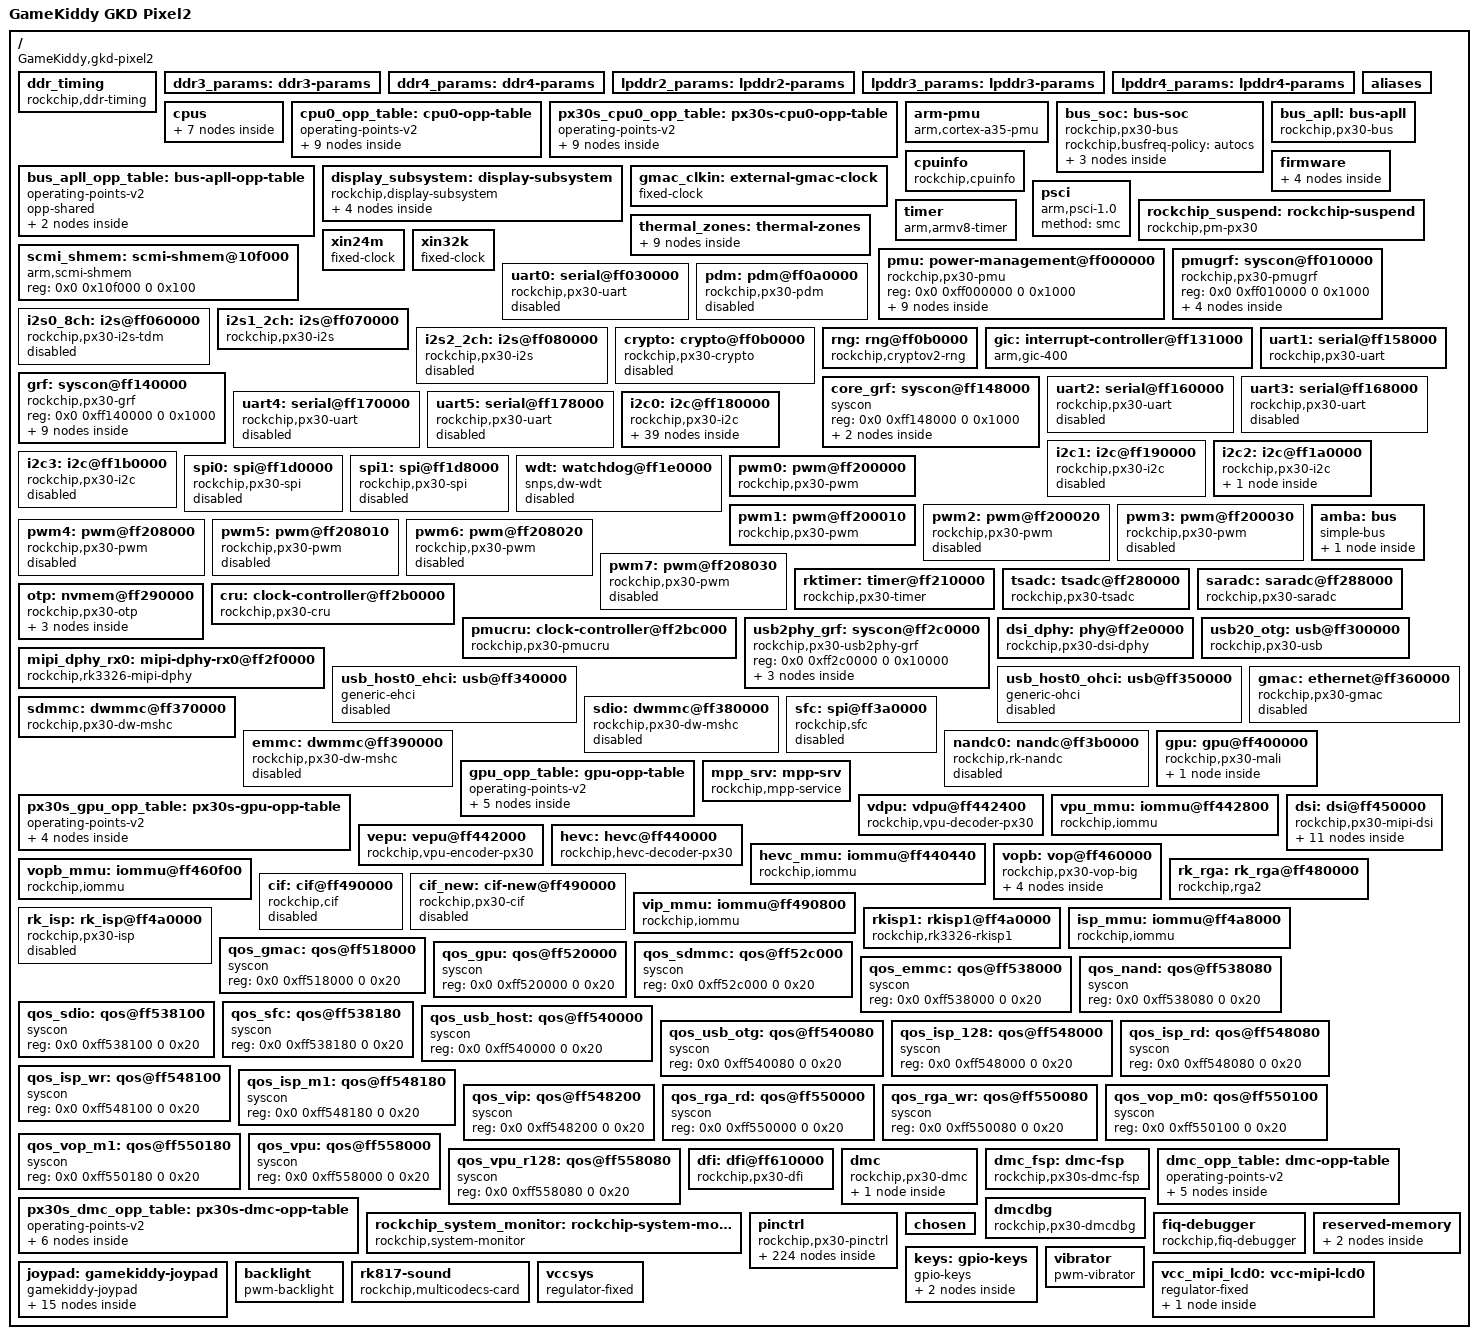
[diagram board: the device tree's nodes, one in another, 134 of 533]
#include <dt-bindings/interrupt-controller/arm-gic.h>
#include <dt-bindings/interrupt-controller/irq.h>
#include <dt-bindings/pinctrl/rockchip.h>
#include <dt-bindings/gpio/gpio.h>

/ {
    compatible = "GameKiddy,gkd-pixel2", "rockchip,rk3326";
    interrupt-parent = <&gic>;
    #address-cells = <2>;
    #size-cells = <2>;
    model = "GameKiddy GKD Pixel2";
    ddr_timing: ddr_timing {
        compatible = "rockchip,ddr-timing";
        ddr2_speed_bin = <0>;
        ddr3_speed_bin = <21>;
        ddr4_speed_bin = <12>;
        pd_idle = <13>;
        sr_idle = <93>;
        sr_mc_gate_idle = <0>;
        srpd_lite_idle = <0>;
        standby_idle = <0>;
        auto_pd_dis_freq = <1066>;
        auto_sr_dis_freq = <800>;
        ddr2_dll_dis_freq = <300>;
        ddr3_dll_dis_freq = <300>;
        ddr4_dll_dis_freq = <625>;
        phy_dll_dis_freq = <400>;
        ddr2_odt_dis_freq = <100>;
        phy_ddr2_odt_dis_freq = <100>;
        ddr2_drv = <1>;
        ddr2_odt = <150>;
        phy_ddr2_ca_drv = <21>;
        phy_ddr2_ck_drv = <18>;
        phy_ddr2_dq_drv = <21>;
        phy_ddr2_odt = <2>;
        ddr3_odt_dis_freq = <400>;
        phy_ddr3_odt_dis_freq = <400>;
        ddr3_drv = <40>;
        ddr3_odt = <120>;
        phy_ddr3_ca_drv = <21>;
        phy_ddr3_ck_drv = <18>;
        phy_ddr3_dq_drv = <21>;
        phy_ddr3_odt = <2>;
        phy_lpddr2_odt_dis_freq = <666>;
        lpddr2_drv = <40>;
        phy_lpddr2_ca_drv = <22>;
        phy_lpddr2_ck_drv = <19>;
        phy_lpddr2_dq_drv = <22>;
        phy_lpddr2_odt = <0>;
        lpddr3_odt_dis_freq = <400>;
        phy_lpddr3_odt_dis_freq = <400>;
        lpddr3_drv = <40>;
        lpddr3_odt = <240>;
        phy_lpddr3_ca_drv = <22>;
        phy_lpddr3_ck_drv = <19>;
        phy_lpddr3_dq_drv = <22>;
        phy_lpddr3_odt = <2>;
        lpddr4_odt_dis_freq = <800>;
        phy_lpddr4_odt_dis_freq = <800>;
        lpddr4_drv = <60>;
        lpddr4_dq_odt = <40>;
        lpddr4_ca_odt = <40>;
        phy_lpddr4_ca_drv = <20>;
        phy_lpddr4_ck_cs_drv = <6>;
        phy_lpddr4_dq_drv = <6>;
        phy_lpddr4_odt = <16>;
        ddr4_odt_dis_freq = <625>;
        phy_ddr4_odt_dis_freq = <625>;
        ddr4_drv = <34>;
        ddr4_odt = <240>;
        phy_ddr4_ca_drv = <22>;
        phy_ddr4_ck_drv = <19>;
        phy_ddr4_dq_drv = <22>;
        phy_ddr4_odt = <2>;
        ddr3a1_ddr4a9_de-skew = <6>;
        ddr3a0_ddr4a10_de-skew = <7>;
        ddr3a3_ddr4a6_de-skew = <7>;
        ddr3a2_ddr4a4_de-skew = <7>;
        ddr3a5_ddr4a8_de-skew = <7>;
        ddr3a4_ddr4a5_de-skew = <7>;
        ddr3a7_ddr4a11_de-skew = <7>;
        ddr3a6_ddr4a7_de-skew = <6>;
        ddr3a9_ddr4a0_de-skew = <7>;
        ddr3a8_ddr4a13_de-skew = <7>;
        ddr3a11_ddr4a3_de-skew = <7>;
        ddr3a10_ddr4cs0_de-skew = <7>;
        ddr3a13_ddr4a2_de-skew = <7>;
        ddr3a12_ddr4ba1_de-skew = <7>;
        ddr3a15_ddr4odt0_de-skew = <7>;
        ddr3a14_ddr4a1_de-skew = <7>;
        ddr3ba1_ddr4a15_de-skew = <7>;
        ddr3ba0_ddr4bg0_de-skew = <7>;
        ddr3ras_ddr4cke_de-skew = <7>;
        ddr3ba2_ddr4ba0_de-skew = <7>;
        ddr3we_ddr4bg1_de-skew = <7>;
        ddr3cas_ddr4a12_de-skew = <7>;
        ddr3ckn_ddr4ckn_de-skew = <7>;
        ddr3ckp_ddr4ckp_de-skew = <7>;
        ddr3cke_ddr4a16_de-skew = <7>;
        ddr3odt0_ddr4a14_de-skew = <7>;
        ddr3cs0_ddr4act_de-skew = <6>;
        ddr3reset_ddr4reset_de-skew = <7>;
        ddr3cs1_ddr4cs1_de-skew = <6>;
        ddr3odt1_ddr4odt1_de-skew = <7>;
        cs0_dm0_rx_de-skew = <7>;
        cs0_dm0_tx_de-skew = <7>;
        cs0_dq0_rx_de-skew = <8>;
        cs0_dq0_tx_de-skew = <8>;
        cs0_dq1_rx_de-skew = <9>;
        cs0_dq1_tx_de-skew = <8>;
        cs0_dq2_rx_de-skew = <8>;
        cs0_dq2_tx_de-skew = <8>;
        cs0_dq3_rx_de-skew = <8>;
        cs0_dq3_tx_de-skew = <8>;
        cs0_dq4_rx_de-skew = <9>;
        cs0_dq4_tx_de-skew = <8>;
        cs0_dq5_rx_de-skew = <9>;
        cs0_dq5_tx_de-skew = <8>;
        cs0_dq6_rx_de-skew = <9>;
        cs0_dq6_tx_de-skew = <8>;
        cs0_dq7_rx_de-skew = <8>;
        cs0_dq7_tx_de-skew = <8>;
        cs0_dqs0_rx_de-skew = <6>;
        cs0_dqs0p_tx_de-skew = <9>;
        cs0_dqs0n_tx_de-skew = <9>;
        cs0_dm1_rx_de-skew = <7>;
        cs0_dm1_tx_de-skew = <6>;
        cs0_dq8_rx_de-skew = <8>;
        cs0_dq8_tx_de-skew = <7>;
        cs0_dq9_rx_de-skew = <9>;
        cs0_dq9_tx_de-skew = <7>;
        cs0_dq10_rx_de-skew = <8>;
        cs0_dq10_tx_de-skew = <8>;
        cs0_dq11_rx_de-skew = <8>;
        cs0_dq11_tx_de-skew = <7>;
        cs0_dq12_rx_de-skew = <8>;
        cs0_dq12_tx_de-skew = <8>;
        cs0_dq13_rx_de-skew = <9>;
        cs0_dq13_tx_de-skew = <7>;
        cs0_dq14_rx_de-skew = <9>;
        cs0_dq14_tx_de-skew = <8>;
        cs0_dq15_rx_de-skew = <9>;
        cs0_dq15_tx_de-skew = <7>;
        cs0_dqs1_rx_de-skew = <7>;
        cs0_dqs1p_tx_de-skew = <9>;
        cs0_dqs1n_tx_de-skew = <9>;
        cs0_dm2_rx_de-skew = <7>;
        cs0_dm2_tx_de-skew = <7>;
        cs0_dq16_rx_de-skew = <9>;
        cs0_dq16_tx_de-skew = <9>;
        cs0_dq17_rx_de-skew = <7>;
        cs0_dq17_tx_de-skew = <9>;
        cs0_dq18_rx_de-skew = <7>;
        cs0_dq18_tx_de-skew = <8>;
        cs0_dq19_rx_de-skew = <7>;
        cs0_dq19_tx_de-skew = <9>;
        cs0_dq20_rx_de-skew = <9>;
        cs0_dq20_tx_de-skew = <9>;
        cs0_dq21_rx_de-skew = <9>;
        cs0_dq21_tx_de-skew = <9>;
        cs0_dq22_rx_de-skew = <8>;
        cs0_dq22_tx_de-skew = <9>;
        cs0_dq23_rx_de-skew = <8>;
        cs0_dq23_tx_de-skew = <9>;
        cs0_dqs2_rx_de-skew = <6>;
        cs0_dqs2p_tx_de-skew = <9>;
        cs0_dqs2n_tx_de-skew = <9>;
        cs0_dm3_rx_de-skew = <7>;
        cs0_dm3_tx_de-skew = <7>;
        cs0_dq24_rx_de-skew = <8>;
        cs0_dq24_tx_de-skew = <8>;
        cs0_dq25_rx_de-skew = <9>;
        cs0_dq25_tx_de-skew = <9>;
        cs0_dq26_rx_de-skew = <9>;
        cs0_dq26_tx_de-skew = <8>;
        cs0_dq27_rx_de-skew = <9>;
        cs0_dq27_tx_de-skew = <8>;
        cs0_dq28_rx_de-skew = <9>;
        cs0_dq28_tx_de-skew = <9>;
        cs0_dq29_rx_de-skew = <9>;
        cs0_dq29_tx_de-skew = <9>;
        cs0_dq30_rx_de-skew = <8>;
        cs0_dq30_tx_de-skew = <8>;
        cs0_dq31_rx_de-skew = <8>;
        cs0_dq31_tx_de-skew = <8>;
        cs0_dqs3_rx_de-skew = <7>;
        cs0_dqs3p_tx_de-skew = <9>;
        cs0_dqs3n_tx_de-skew = <9>;
        cs1_dm0_rx_de-skew = <7>;
        cs1_dm0_tx_de-skew = <7>;
        cs1_dq0_rx_de-skew = <8>;
        cs1_dq0_tx_de-skew = <8>;
        cs1_dq1_rx_de-skew = <9>;
        cs1_dq1_tx_de-skew = <8>;
        cs1_dq2_rx_de-skew = <8>;
        cs1_dq2_tx_de-skew = <8>;
        cs1_dq3_rx_de-skew = <8>;
        cs1_dq3_tx_de-skew = <8>;
        cs1_dq4_rx_de-skew = <8>;
        cs1_dq4_tx_de-skew = <8>;
        cs1_dq5_rx_de-skew = <9>;
        cs1_dq5_tx_de-skew = <8>;
        cs1_dq6_rx_de-skew = <9>;
        cs1_dq6_tx_de-skew = <8>;
        cs1_dq7_rx_de-skew = <8>;
        cs1_dq7_tx_de-skew = <8>;
        cs1_dqs0_rx_de-skew = <6>;
        cs1_dqs0p_tx_de-skew = <9>;
        cs1_dqs0n_tx_de-skew = <9>;
        cs1_dm1_rx_de-skew = <7>;
        cs1_dm1_tx_de-skew = <7>;
        cs1_dq8_rx_de-skew = <8>;
        cs1_dq8_tx_de-skew = <8>;
        cs1_dq9_rx_de-skew = <8>;
        cs1_dq9_tx_de-skew = <7>;
        cs1_dq10_rx_de-skew = <7>;
        cs1_dq10_tx_de-skew = <8>;
        cs1_dq11_rx_de-skew = <8>;
        cs1_dq11_tx_de-skew = <8>;
        cs1_dq12_rx_de-skew = <8>;
        cs1_dq12_tx_de-skew = <7>;
        cs1_dq13_rx_de-skew = <8>;
        cs1_dq13_tx_de-skew = <8>;
        cs1_dq14_rx_de-skew = <8>;
        cs1_dq14_tx_de-skew = <8>;
        cs1_dq15_rx_de-skew = <8>;
        cs1_dq15_tx_de-skew = <7>;
        cs1_dqs1_rx_de-skew = <7>;
        cs1_dqs1p_tx_de-skew = <9>;
        cs1_dqs1n_tx_de-skew = <9>;
        cs1_dm2_rx_de-skew = <7>;
        cs1_dm2_tx_de-skew = <8>;
        cs1_dq16_rx_de-skew = <8>;
        cs1_dq16_tx_de-skew = <9>;
        cs1_dq17_rx_de-skew = <8>;
        cs1_dq17_tx_de-skew = <9>;
        cs1_dq18_rx_de-skew = <7>;
        cs1_dq18_tx_de-skew = <8>;
        cs1_dq19_rx_de-skew = <8>;
        cs1_dq19_tx_de-skew = <9>;
        cs1_dq20_rx_de-skew = <9>;
        cs1_dq20_tx_de-skew = <9>;
        cs1_dq21_rx_de-skew = <9>;
        cs1_dq21_tx_de-skew = <9>;
        cs1_dq22_rx_de-skew = <8>;
        cs1_dq22_tx_de-skew = <9>;
        cs1_dq23_rx_de-skew = <8>;
        cs1_dq23_tx_de-skew = <9>;
        cs1_dqs2_rx_de-skew = <6>;
        cs1_dqs2p_tx_de-skew = <9>;
        cs1_dqs2n_tx_de-skew = <9>;
        cs1_dm3_rx_de-skew = <7>;
        cs1_dm3_tx_de-skew = <7>;
        cs1_dq24_rx_de-skew = <8>;
        cs1_dq24_tx_de-skew = <9>;
        cs1_dq25_rx_de-skew = <9>;
        cs1_dq25_tx_de-skew = <9>;
        cs1_dq26_rx_de-skew = <9>;
        cs1_dq26_tx_de-skew = <8>;
        cs1_dq27_rx_de-skew = <8>;
        cs1_dq27_tx_de-skew = <8>;
        cs1_dq28_rx_de-skew = <9>;
        cs1_dq28_tx_de-skew = <9>;
        cs1_dq29_rx_de-skew = <9>;
        cs1_dq29_tx_de-skew = <9>;
        cs1_dq30_rx_de-skew = <9>;
        cs1_dq30_tx_de-skew = <8>;
        cs1_dq31_rx_de-skew = <8>;
        cs1_dq31_tx_de-skew = <8>;
        cs1_dqs3_rx_de-skew = <7>;
        cs1_dqs3p_tx_de-skew = <9>;
        cs1_dqs3n_tx_de-skew = <9>;
    };
    ddr3_params: ddr3-params {
        version = <257>;
        expanded_version = <0>;
        reserved = <0>;
        freq_0 = <666>;
        freq_1 = <194>;
        freq_2 = <328>;
        freq_3 = <666>;
        freq_4 = <0>;
        freq_5 = <0>;
        pd_idle = <13>;
        sr_idle = <93>;
        sr_mc_gate_idle = <0>;
        srpd_lite_idle = <0>;
        standby_idle = <0>;
        pd_dis_freq = <1066>;
        sr_dis_freq = <800>;
        dram_dll_dis_freq = <300>;
        phy_dll_dis_freq = <0>;
        phy_dq_drv_odten = <33>;
        phy_ca_drv_odten = <33>;
        phy_clk_drv_odten = <33>;
        dram_dq_drv_odten = <34>;
        phy_dq_drv_odtoff = <33>;
        phy_ca_drv_odtoff = <33>;
        phy_clk_drv_odtoff = <33>;
        dram_dq_drv_odtoff = <34>;
        dram_odt = <120>;
        phy_odt = <133>;
        phy_odt_puup_en = <1>;
        phy_odt_pudn_en = <1>;
        dram_dq_odt_en_freq = <333>;
        phy_odt_en_freq = <333>;
        phy_dq_sr_odten = <15>;
        phy_ca_sr_odten = <3>;
        phy_clk_sr_odten = <3>;
        phy_dq_sr_odtoff = <15>;
        phy_ca_sr_odtoff = <3>;
        phy_clk_sr_odtoff = <3>;
        ssmod_downspread = <0>;
        ssmod_div = <0>;
        ssmod_spread = <0>;
        mode_2t = <0>;
        speed_bin = <21>;
        dram_ext_temp = <0>;
        byte_map = <177>;
        dq_map_cs0_dq_l = <0>;
        dq_map_cs0_dq_h = <0>;
        dq_map_cs1_dq_l = <0>;
        dq_map_cs1_dq_h = <0>;
    };
    ddr4_params: ddr4-params {
        version = <257>;
        expanded_version = <0>;
        reserved = <0>;
        freq_0 = <666>;
        freq_1 = <194>;
        freq_2 = <328>;
        freq_3 = <666>;
        freq_4 = <0>;
        freq_5 = <0>;
        pd_idle = <13>;
        sr_idle = <93>;
        sr_mc_gate_idle = <0>;
        srpd_lite_idle = <0>;
        standby_idle = <0>;
        pd_dis_freq = <1066>;
        sr_dis_freq = <800>;
        dram_dll_dis_freq = <500>;
        phy_dll_dis_freq = <0>;
        phy_dq_drv_odten = <33>;
        phy_ca_drv_odten = <33>;
        phy_clk_drv_odten = <33>;
        dram_dq_drv_odten = <34>;
        phy_dq_drv_odtoff = <33>;
        phy_ca_drv_odtoff = <33>;
        phy_clk_drv_odtoff = <33>;
        dram_dq_drv_odtoff = <34>;
        dram_odt = <120>;
        phy_odt = <121>;
        phy_odt_puup_en = <1>;
        phy_odt_pudn_en = <1>;
        dram_dq_odt_en_freq = <500>;
        phy_odt_en_freq = <500>;
        phy_dq_sr_odten = <14>;
        phy_ca_sr_odten = <1>;
        phy_clk_sr_odten = <1>;
        phy_dq_sr_odtoff = <14>;
        phy_ca_sr_odtoff = <1>;
        phy_clk_sr_odtoff = <1>;
        ssmod_downspread = <0>;
        ssmod_div = <0>;
        ssmod_spread = <0>;
        mode_2t = <0>;
        speed_bin = <12>;
        dram_ext_temp = <0>;
        byte_map = <177>;
        dq_map_cs0_dq_l = <328950387>;
        dq_map_cs0_dq_h = <657289026>;
        dq_map_cs1_dq_l = <1187919654>;
        dq_map_cs1_dq_h = <1920481815>;
    };
    lpddr2_params: lpddr2-params {
        version = <257>;
        expanded_version = <0>;
        reserved = <0>;
        freq_0 = <528>;
        freq_1 = <194>;
        freq_2 = <328>;
        freq_3 = <528>;
        freq_4 = <0>;
        freq_5 = <0>;
        pd_idle = <13>;
        sr_idle = <93>;
        sr_mc_gate_idle = <0>;
        srpd_lite_idle = <0>;
        standby_idle = <0>;
        pd_dis_freq = <1066>;
        sr_dis_freq = <800>;
        dram_dll_dis_freq = <0>;
        phy_dll_dis_freq = <0>;
        phy_dq_drv_odten = <33>;
        phy_ca_drv_odten = <33>;
        phy_clk_drv_odten = <33>;
        dram_dq_drv_odten = <34>;
        phy_dq_drv_odtoff = <33>;
        phy_ca_drv_odtoff = <33>;
        phy_clk_drv_odtoff = <33>;
        dram_dq_drv_odtoff = <34>;
        dram_odt = <0>;
        phy_odt = <0>;
        phy_odt_puup_en = <0>;
        phy_odt_pudn_en = <0>;
        dram_dq_odt_en_freq = <625>;
        phy_odt_en_freq = <625>;
        phy_dq_sr_odten = <14>;
        phy_ca_sr_odten = <1>;
        phy_clk_sr_odten = <1>;
        phy_dq_sr_odtoff = <14>;
        phy_ca_sr_odtoff = <1>;
        phy_clk_sr_odtoff = <1>;
        ssmod_downspread = <0>;
        ssmod_div = <0>;
        ssmod_spread = <0>;
        mode_2t = <0>;
        speed_bin = <0>;
        dram_ext_temp = <0>;
        byte_map = <228>;
        dq_map_cs0_dq_l = <0>;
        dq_map_cs0_dq_h = <0>;
        dq_map_cs1_dq_l = <0>;
        dq_map_cs1_dq_h = <0>;
    };
    lpddr3_params: lpddr3-params {
        version = <257>;
        expanded_version = <0>;
        reserved = <0>;
        freq_0 = <666>;
        freq_1 = <194>;
        freq_2 = <328>;
        freq_3 = <666>;
        freq_4 = <0>;
        freq_5 = <0>;
        pd_idle = <13>;
        sr_idle = <93>;
        sr_mc_gate_idle = <0>;
        srpd_lite_idle = <0>;
        standby_idle = <0>;
        pd_dis_freq = <1066>;
        sr_dis_freq = <800>;
        dram_dll_dis_freq = <0>;
        phy_dll_dis_freq = <0>;
        phy_dq_drv_odten = <33>;
        phy_ca_drv_odten = <33>;
        phy_clk_drv_odten = <33>;
        dram_dq_drv_odten = <34>;
        phy_dq_drv_odtoff = <33>;
        phy_ca_drv_odtoff = <33>;
        phy_clk_drv_odtoff = <33>;
        dram_dq_drv_odtoff = <34>;
        dram_odt = <240>;
        phy_odt = <121>;
        phy_odt_puup_en = <1>;
        phy_odt_pudn_en = <1>;
        dram_dq_odt_en_freq = <333>;
        phy_odt_en_freq = <333>;
        phy_dq_sr_odten = <0>;
        phy_ca_sr_odten = <0>;
        phy_clk_sr_odten = <0>;
        phy_dq_sr_odtoff = <0>;
        phy_ca_sr_odtoff = <0>;
        phy_clk_sr_odtoff = <0>;
        ssmod_downspread = <0>;
        ssmod_div = <0>;
        ssmod_spread = <0>;
        mode_2t = <0>;
        speed_bin = <0>;
        dram_ext_temp = <0>;
        byte_map = <228>;
        dq_map_cs0_dq_l = <0>;
        dq_map_cs0_dq_h = <0>;
        dq_map_cs1_dq_l = <0>;
        dq_map_cs1_dq_h = <0>;
    };
    lpddr4_params: lpddr4-params {
        version = <257>;
        expanded_version = <0>;
        reserved = <0>;
        freq_0 = <1056>;
        freq_1 = <194>;
        freq_2 = <328>;
        freq_3 = <1056>;
        freq_4 = <0>;
        freq_5 = <0>;
        pd_idle = <13>;
        sr_idle = <93>;
        sr_mc_gate_idle = <0>;
        srpd_lite_idle = <0>;
        standby_idle = <0>;
        pd_dis_freq = <1066>;
        sr_dis_freq = <800>;
        dram_dll_dis_freq = <0>;
        phy_dll_dis_freq = <0>;
        phy_dq_drv_odten = <44>;
        phy_ca_drv_odten = <38>;
        phy_clk_drv_odten = <47>;
        dram_dq_drv_odten = <40>;
        phy_dq_drv_odtoff = <44>;
        phy_ca_drv_odtoff = <38>;
        phy_clk_drv_odtoff = <47>;
        dram_dq_drv_odtoff = <40>;
        dram_odt = <60>;
        phy_odt = <80>;
        phy_odt_puup_en = <0>;
        phy_odt_pudn_en = <0>;
        dram_dq_odt_en_freq = <800>;
        phy_odt_en_freq = <800>;
        phy_dq_sr_odten = <7>;
        phy_ca_sr_odten = <1>;
        phy_clk_sr_odten = <1>;
        phy_dq_sr_odtoff = <7>;
        phy_ca_sr_odtoff = <1>;
        phy_clk_sr_odtoff = <1>;
        ssmod_downspread = <0>;
        ssmod_div = <0>;
        ssmod_spread = <0>;
        mode_2t = <0>;
        speed_bin = <0>;
        dram_ext_temp = <0>;
        byte_map = <228>;
        dq_map_cs0_dq_l = <0>;
        dq_map_cs0_dq_h = <0>;
        dq_map_cs1_dq_l = <0>;
        dq_map_cs1_dq_h = <0>;
        lp4_ca_odt = <120>;
        lp4_drv_pu_cal_odten = <0>;
        lp4_drv_pu_cal_odtoff = <0>;
        phy_lp4_drv_pulldown_en_odten = <0>;
        phy_lp4_drv_pulldown_en_odtoff = <0>;
        lp4_ca_odt_en_freq = <800>;
        phy_lp4_cs_drv_odten = <0>;
        phy_lp4_cs_drv_odtoff = <0>;
        lp4_odte_ck_en = <1>;
        lp4_odte_cs_en = <1>;
        lp4_odtd_ca_en = <0>;
        phy_lp4_dq_vref_odten = <200>;
        lp4_dq_vref_odten = <276>;
        lp4_ca_vref_odten = <380>;
        phy_lp4_dq_vref_odtoff = <420>;
        lp4_dq_vref_odtoff = <420>;
        lp4_ca_vref_odtoff = <420>;
    };
    aliases {
        ethernet0 = "/ethernet@ff360000";
        gpio0 = "/pinctrl/gpio0@ff040000";
        gpio1 = "/pinctrl/gpio1@ff250000";
        gpio2 = "/pinctrl/gpio2@ff260000";
        gpio3 = "/pinctrl/gpio3@ff270000";
        i2c0 = "/i2c@ff180000";
        i2c1 = "/i2c@ff190000";
        i2c2 = "/i2c@ff1a0000";
        i2c3 = "/i2c@ff1b0000";
        mmc0 = "/dwmmc@ff370000";
        mmc1 = "/dwmmc@ff380000";
        mmc2 = "/dwmmc@ff390000";
        serial0 = "/serial@ff030000";
        serial1 = "/serial@ff158000";
        serial2 = "/serial@ff160000";
        serial3 = "/serial@ff168000";
        serial4 = "/serial@ff170000";
        serial5 = "/serial@ff178000";
        spi0 = "/spi@ff1d0000";
        spi1 = "/spi@ff1d8000";
        spi2 = "/spi@ff3a0000";
    };
    cpus {
        #address-cells = <2>;
        #size-cells = <0>;
        cpu0: cpu@0 {
            device_type = "cpu";
            compatible = "arm,cortex-a35";
            reg = <0x0 0x0>;
            enable-method = "psci";
            clocks = <&cru 7>;
            #cooling-cells = <2>;
            cpu-idle-states = <&CPU_SLEEP &CLUSTER_SLEEP>;
            dynamic-power-coefficient = <90>;
            operating-points-v2 = <&cpu0_opp_table>;
            cpu-supply = <&vdd_arm>;
        };
        cpu1: cpu@1 {
            device_type = "cpu";
            compatible = "arm,cortex-a35";
            reg = <0x0 0x1>;
            enable-method = "psci";
            clocks = <&cru 7>;
            #cooling-cells = <2>;
            cpu-idle-states = <&CPU_SLEEP &CLUSTER_SLEEP>;
            dynamic-power-coefficient = <90>;
            operating-points-v2 = <&cpu0_opp_table>;
        };
        cpu2: cpu@2 {
            device_type = "cpu";
            compatible = "arm,cortex-a35";
            reg = <0x0 0x2>;
            enable-method = "psci";
            clocks = <&cru 7>;
            #cooling-cells = <2>;
            cpu-idle-states = <&CPU_SLEEP &CLUSTER_SLEEP>;
            dynamic-power-coefficient = <90>;
            operating-points-v2 = <&cpu0_opp_table>;
        };
        cpu3: cpu@3 {
            device_type = "cpu";
            compatible = "arm,cortex-a35";
            reg = <0x0 0x3>;
            enable-method = "psci";
            clocks = <&cru 7>;
            #cooling-cells = <2>;
            cpu-idle-states = <&CPU_SLEEP &CLUSTER_SLEEP>;
            dynamic-power-coefficient = <90>;
            operating-points-v2 = <&cpu0_opp_table>;
        };
        idle-states {
            entry-method = "psci";
            CPU_SLEEP: cpu-sleep {
                compatible = "arm,idle-state";
                local-timer-stop;
                arm,psci-suspend-param = <65536>;
                entry-latency-us = <120>;
                exit-latency-us = <250>;
                min-residency-us = <900>;
            };
            CLUSTER_SLEEP: cluster-sleep {
                compatible = "arm,idle-state";
                local-timer-stop;
                arm,psci-suspend-param = <16842752>;
                entry-latency-us = <400>;
                exit-latency-us = <500>;
                min-residency-us = <2000>;
            };
        };
    };
    cpu0_opp_table: cpu0-opp-table {
        compatible = "operating-points-v2";
        opp-shared;
        rockchip,temp-hysteresis = <5000>;
        rockchip,low-temp = <0>;
        rockchip,low-temp-min-volt = <1000000>;
        rockchip,low-temp-adjust-volt = <0 1512 50000>;
        clocks = <&cru 1>;
        rockchip,avs-scale = <4>;
        rockchip,max-volt = <1350000>;
        rockchip,evb-irdrop = <25000>;
        nvmem-cells = <7 8>;
        nvmem-cell-names = "cpu_leakage", "performance";
        rockchip,bin-scaling-sel = <0 13 1 15>;
        rockchip,pvtm-voltage-sel = <0 50000 0 50001 54000 1 54001 60000 2 60001 99999 3>;
        rockchip,pvtm-freq = <408000>;
        rockchip,pvtm-volt = <1000000>;
        rockchip,pvtm-ch = <0 0>;
        rockchip,pvtm-sample-time = <1000>;
        rockchip,pvtm-number = <10>;
        rockchip,pvtm-error = <1000>;
        rockchip,pvtm-ref-temp = <40>;
        rockchip,pvtm-temp-prop = <4294967240 4294967240>;
        rockchip,thermal-zone = "soc-thermal";
        rockchip,avs = <1>;
        opp-408000000 {
            opp-hz = <0 408000000>;
            opp-microvolt = <950000 950000 1350000>;
            opp-microvolt-L0 = <950000 950000 1350000>;
            opp-microvolt-L1 = <950000 950000 1350000>;
            opp-microvolt-L2 = <950000 950000 1350000>;
            opp-microvolt-L3 = <950000 950000 1350000>;
            clock-latency-ns = <40000>;
            opp-suspend;
        };
        opp-600000000 {
            opp-hz = <0 600000000>;
            opp-microvolt = <950000 950000 1350000>;
            opp-microvolt-L0 = <950000 950000 1350000>;
            opp-microvolt-L1 = <950000 950000 1350000>;
            opp-microvolt-L2 = <950000 950000 1350000>;
            opp-microvolt-L3 = <950000 950000 1350000>;
            clock-latency-ns = <40000>;
        };
        opp-816000000 {
            opp-hz = <0 816000000>;
            opp-microvolt = <1050000 1050000 1350000>;
            opp-microvolt-L0 = <1050000 1050000 1350000>;
            opp-microvolt-L1 = <1000000 1000000 1350000>;
            opp-microvolt-L2 = <1000000 1000000 1350000>;
            opp-microvolt-L3 = <950000 950000 1350000>;
            clock-latency-ns = <40000>;
        };
        opp-1008000000 {
            opp-hz = <0 1008000000>;
            opp-microvolt = <1175000 1175000 1350000>;
            opp-microvolt-L0 = <1175000 1175000 1350000>;
            opp-microvolt-L1 = <1125000 1125000 1350000>;
            opp-microvolt-L2 = <1125000 1125000 1350000>;
            opp-microvolt-L3 = <1050000 1050000 1350000>;
            clock-latency-ns = <40000>;
        };
        opp-1200000000 {
            opp-hz = <0 1200000000>;
            opp-microvolt = <1300000 1300000 1350000>;
            opp-microvolt-L0 = <1300000 1300000 1350000>;
            opp-microvolt-L1 = <1275000 1275000 1350000>;
            opp-microvolt-L2 = <1250000 1250000 1350000>;
            opp-microvolt-L3 = <1200000 1200000 1350000>;
            clock-latency-ns = <40000>;
        };
        opp-1248000000 {
            opp-hz = <0 1248000000>;
            opp-microvolt = <1350000 1350000 1350000>;
            opp-microvolt-L0 = <1350000 1350000 1350000>;
            opp-microvolt-L1 = <1300000 1300000 1350000>;
            opp-microvolt-L2 = <1275000 1275000 1350000>;
            opp-microvolt-L3 = <1225000 1225000 1350000>;
            clock-latency-ns = <40000>;
        };
        opp-1296000000 {
            opp-hz = <0 1296000000>;
            opp-microvolt = <1350000 1350000 1350000>;
            opp-microvolt-L0 = <1350000 1350000 1350000>;
            opp-microvolt-L1 = <1350000 1350000 1350000>;
            opp-microvolt-L2 = <1300000 1300000 1350000>;
            opp-microvolt-L3 = <1250000 1250000 1350000>;
            clock-latency-ns = <40000>;
        };
        opp-1416000000 {
            opp-hz = <0 1416000000>;
            opp-microvolt = <1350000 1350000 1350000>;
            opp-microvolt-L0 = <1350000 1350000 1350000>;
            opp-microvolt-L1 = <1350000 1350000 1350000>;
            opp-microvolt-L2 = <1300000 1300000 1350000>;
            opp-microvolt-L3 = <1250000 1250000 1350000>;
            clock-latency-ns = <40000>;
        };
        opp-1512000000 {
            opp-hz = <0 1512000000>;
            opp-microvolt = <1350000 1350000 1350000>;
            opp-microvolt-L0 = <1350000 1350000 1350000>;
            opp-microvolt-L1 = <1350000 1350000 1350000>;
            opp-microvolt-L2 = <1300000 1300000 1350000>;
            opp-microvolt-L3 = <1250000 1250000 1350000>;
            clock-latency-ns = <40000>;
        };
    };
    px30s_cpu0_opp_table: px30s-cpu0-opp-table {
        compatible = "operating-points-v2";
        opp-shared;
        nvmem-cells = <7>;
        nvmem-cell-names = "cpu_leakage";
        rockchip,pvtm-voltage-sel = <0 69850 0 69851 73800 1 73801 77750 2 77751 81700 3 81701 99999 4>;
        rockchip,pvtm-freq = <408000>;
        rockchip,pvtm-volt = <900000>;
        rockchip,pvtm-ch = <0 0>;
        rockchip,pvtm-sample-time = <1000>;
        rockchip,pvtm-number = <10>;
        rockchip,pvtm-error = <1000>;
        rockchip,pvtm-ref-temp = <0>;
        rockchip,pvtm-temp-prop = <0 0>;
        rockchip,thermal-zone = "soc-thermal";
        opp-408000000 {
            opp-hz = <0 408000000>;
            opp-microvolt = <850000 850000 1150000>;
            clock-latency-ns = <40000>;
            opp-suspend;
        };
        opp-600000000 {
            opp-hz = <0 600000000>;
            opp-microvolt = <850000 850000 1150000>;
            clock-latency-ns = <40000>;
        };
        opp-816000000 {
            opp-hz = <0 816000000>;
            opp-microvolt = <850000 850000 1150000>;
            clock-latency-ns = <40000>;
        };
        opp-1008000000 {
            opp-hz = <0 1008000000>;
            opp-microvolt = <950000 950000 1150000>;
            opp-microvolt-L0 = <950000 950000 1150000>;
            opp-microvolt-L1 = <925000 925000 1150000>;
            opp-microvolt-L2 = <900000 900000 1150000>;
            opp-microvolt-L3 = <875000 875000 1150000>;
            opp-microvolt-L4 = <850000 850000 1150000>;
            clock-latency-ns = <40000>;
        };
        opp-1200000000 {
            opp-hz = <0 1200000000>;
            opp-microvolt = <1050000 1050000 1150000>;
            opp-microvolt-L0 = <1050000 1050000 1150000>;
            opp-microvolt-L1 = <1025000 1025000 1150000>;
            opp-microvolt-L2 = <1000000 1000000 1150000>;
            opp-microvolt-L3 = <975000 975000 1150000>;
            opp-microvolt-L4 = <950000 950000 1150000>;
            clock-latency-ns = <40000>;
        };
        opp-1248000000 {
            opp-hz = <0 1248000000>;
            opp-microvolt = <1075000 1075000 1150000>;
            opp-microvolt-L0 = <1075000 1075000 1150000>;
            opp-microvolt-L1 = <1050000 1050000 1150000>;
            opp-microvolt-L2 = <1025000 1025000 1150000>;
            opp-microvolt-L3 = <1000000 1000000 1150000>;
            opp-microvolt-L4 = <975000 975000 1150000>;
            clock-latency-ns = <40000>;
        };
        opp-1296000000 {
            opp-hz = <0 1296000000>;
            opp-microvolt = <1100000 1100000 1150000>;
            opp-microvolt-L0 = <1100000 1100000 1150000>;
            opp-microvolt-L1 = <1075000 1075000 1150000>;
            opp-microvolt-L2 = <1050000 1050000 1150000>;
            opp-microvolt-L3 = <1025000 1025000 1150000>;
            opp-microvolt-L4 = <1000000 1000000 1150000>;
            clock-latency-ns = <40000>;
        };
        opp-1416000000 {
            opp-hz = <0 1416000000>;
            opp-microvolt = <1150000 1150000 1150000>;
            opp-microvolt-L0 = <1150000 1150000 1150000>;
            opp-microvolt-L1 = <1125000 1125000 1150000>;
            opp-microvolt-L2 = <1100000 1100000 1150000>;
            opp-microvolt-L3 = <1075000 1075000 1150000>;
            opp-microvolt-L4 = <1050000 1050000 1150000>;
            clock-latency-ns = <40000>;
        };
        opp-1512000000 {
            opp-hz = <0 1512000000>;
            opp-microvolt = <1150000 1150000 1150000>;
            opp-microvolt-L0 = <1150000 1150000 1150000>;
            opp-microvolt-L1 = <1125000 1125000 1150000>;
            opp-microvolt-L2 = <1100000 1100000 1150000>;
            opp-microvolt-L3 = <1075000 1075000 1150000>;
            opp-microvolt-L4 = <1050000 1050000 1150000>;
            clock-latency-ns = <40000>;
        };
    };
    arm-pmu {
        compatible = "arm,cortex-a35-pmu";
        interrupts = <GIC_SPI 100 IRQ_TYPE_LEVEL_HIGH>, <GIC_SPI 101 IRQ_TYPE_LEVEL_HIGH>, <GIC_SPI 102 IRQ_TYPE_LEVEL_HIGH>, <GIC_SPI 103 IRQ_TYPE_LEVEL_HIGH>;
        interrupt-affinity = <&cpu0>, <&cpu1>, <&cpu2>, <&cpu3>;
    };
    bus_soc: bus-soc {
        compatible = "rockchip,px30-bus";
        rockchip,busfreq-policy = "autocs";
        soc-bus0 {
            bus-id = <0>;
            timer-us = <20>;
            enable-msk = <16631>;
        };
        soc-bus1 {
            bus-id = <1>;
            timer-us = <200>;
            enable-msk = <16575>;
            status = "disabled";
        };
        soc-bus2 {
            bus-id = <2>;
            timer-us = <200>;
            enable-msk = <16391>;
            status = "disabled";
        };
    };
    bus_apll: bus-apll {
        compatible = "rockchip,px30-bus";
        rockchip,busfreq-policy = "clkfreq";
        clocks = <&cru 1>;
        clock-names = "bus";
        operating-points-v2 = <&bus_apll_opp_table>;
        status = "okay";
        bus-supply = <&vdd_logic>;
    };
    bus_apll_opp_table: bus-apll-opp-table {
        compatible = "operating-points-v2";
        opp-shared;
        opp-1512000000 {
            opp-hz = <0 1512000000>;
            opp-microvolt = <1000000>;
        };
        opp-1008000000 {
            opp-hz = <0 1008000000>;
            opp-microvolt = <950000>;
        };
    };
    cpuinfo {
        compatible = "rockchip,cpuinfo";
        nvmem-cells = <15>;
        nvmem-cell-names = "id";
    };
    display_subsystem: display-subsystem {
        compatible = "rockchip,display-subsystem";
        ports = <&vopb_out>;
        status = "okay";
        logo-memory-region = <17>;
        route {
            route_lvds: route-lvds {
                status = "disabled";
                logo,uboot = "logo.bmp";
                logo,kernel = "logo_kernel.bmp";
                logo,mode = "center";
                charge_logo,mode = "center";
                connect = <18>;
            };
            route_dsi: route-dsi {
                status = "okay";
                logo,uboot = "logo.bmp";
                logo,kernel = "logo_kernel.bmp";
                logo,mode = "center";
                charge_logo,mode = "center";
                connect = <19>;
            };
            route_rgb: route-rgb {
                status = "disabled";
                logo,uboot = "logo.bmp";
                logo,kernel = "logo_kernel.bmp";
                logo,mode = "center";
                charge_logo,mode = "center";
                connect = <20>;
            };
        };
    };
    firmware {
        optee: optee {
            compatible = "linaro,optee-tz";
            method = "smc";
        };
        scmi: scmi {
            compatible = "arm,scmi-smc";
            shmem = <21>;
            arm,smc-id = <2181038096>;
            #address-cells = <1>;
            #size-cells = <0>;
            scmi_clk: protocol@14 {
                reg = <0x14>;
                #clock-cells = <1>;
            };
        };
        sdei: sdei {
            compatible = "arm,sdei-1.0";
            method = "smc";
        };
    };
    gmac_clkin: external-gmac-clock {
        compatible = "fixed-clock";
        clock-frequency = <50000000>;
        clock-output-names = "gmac_clkin";
        #clock-cells = <0>;
    };
    psci {
        compatible = "arm,psci-1.0";
        method = "smc";
    };
    rockchip_suspend: rockchip-suspend {
        compatible = "rockchip,pm-px30";
        status = "okay";
        rockchip,sleep-debug-en = <0>;
        rockchip,sleep-mode-config = <132866>;
        rockchip,wakeup-config = <133>;
    };
    timer {
        compatible = "arm,armv8-timer";
        interrupts = <GIC_PPI 13 3844>, <GIC_PPI 14 3844>, <GIC_PPI 11 3844>, <GIC_PPI 10 3844>;
    };
    thermal_zones: thermal-zones {
        soc_thermal: soc-thermal {
            polling-delay-passive = <20>;
            polling-delay = <1000>;
            sustainable-power = <750>;
            thermal-sensors = <&tsadc 0>;
            trips {
                threshold: trip-point-0 {
                    temperature = <70000>;
                    hysteresis = <2000>;
                    type = "passive";
                };
                target: trip-point-1 {
                    temperature = <85000>;
                    hysteresis = <2000>;
                    type = "passive";
                };
                soc_crit: soc-crit {
                    temperature = <115000>;
                    hysteresis = <2000>;
                    type = "critical";
                };
            };
            cooling-maps {
                map0 {
                    trip = <&target>;
                    cooling-device = <&cpu0 4294967295 4294967295>;
                    contribution = <4096>;
                };
                map1 {
                    trip = <&target>;
                    cooling-device = <&gpu 4294967295 4294967295>;
                    contribution = <4096>;
                };
            };
        };
        gpu_thermal: gpu-thermal {
            polling-delay-passive = <100>;
            polling-delay = <1000>;
            thermal-sensors = <&tsadc 1>;
        };
    };
    xin24m: xin24m {
        compatible = "fixed-clock";
        #clock-cells = <0>;
        clock-frequency = <24000000>;
        clock-output-names = "xin24m";
    };
    xin32k: xin32k {
        compatible = "fixed-clock";
        #clock-cells = <0>;
        clock-frequency = <32768>;
        clock-output-names = "xin32k";
    };
    scmi_shmem: scmi-shmem@10f000 {
        compatible = "arm,scmi-shmem";
        reg = <0x0 0x10f000 0 0x100>;
    };
    pmu: power-management@ff000000 {
        compatible = "rockchip,px30-pmu", "syscon", "simple-mfd";
        reg = <0x0 0xff000000 0 0x1000>;
        power: power-controller {
            compatible = "rockchip,px30-power-controller";
            #power-domain-cells = <1>;
            #address-cells = <1>;
            #size-cells = <0>;
            power-domain@5 {
                reg = <0x5>;
                clocks = <&cru 259>, <&cru 258>, <&cru 60>;
                pm_qos = <&qos_usb_host>, <&qos_usb_otg>;
            };
            power-domain@7 {
                reg = <0x7>;
                clocks = <&cru 247>, <&cru 59>;
                pm_qos = <&qos_sdmmc>;
            };
            power-domain@9 {
                reg = <0x9>;
                clocks = <&cru 178>, <&cru 323>, <&cru 64>, <&cru 63>;
                pm_qos = <&qos_gmac>;
            };
            power-domain@10 {
                reg = <0xa>;
                clocks = <&cru 254>, <&cru 256>, <&cru 255>, <&cru 257>, <&cru 57>, <&cru 55>, <&cru 56>, <&cru 58>;
                pm_qos = <&qos_emmc>, <&qos_nand>, <&qos_sdio>, <&qos_sfc>;
            };
            power-domain@11 {
                reg = <0xb>;
                clocks = <&cru 175>, <&cru 244>, <&cru 75>;
                pm_qos = <&qos_vpu>, <&qos_vpu_r128>;
            };
            power-domain@12 {
                reg = <0xc>;
                clocks = <&cru 183>, <&cru 181>, <&cru 182>, <&cru 150>, <&cru 151>, <&cru 253>, <&cru 251>, <&cru 252>, <&cru 324>, <&cru 53>, <&cru 54>;
                pm_qos = <&qos_rga_rd>, <&qos_rga_wr>, <&qos_vop_m0>, <&qos_vop_m1>;
            };
            power-domain@13 {
                reg = <0xd>;
                clocks = <&cru 179>, <&cru 180>, <&cru 249>, <&cru 250>, <&cru 51>;
                pm_qos = <&qos_isp_128>, <&qos_isp_rd>, <&qos_isp_wr>, <&qos_isp_m1>, <&qos_vip>;
            };
            power-domain@14 {
                reg = <0xe>;
                clocks = <&cru 73>;
                pm_qos = <&qos_gpu>;
            };
        };
    };
    pmugrf: syscon@ff010000 {
        compatible = "rockchip,px30-pmugrf", "syscon", "simple-mfd";
        reg = <0x0 0xff010000 0 0x1000>;
        #address-cells = <1>;
        #size-cells = <1>;
        pmu_io_domains: io-domains {
            compatible = "rockchip,px30-pmu-io-voltage-domain";
            status = "okay";
            pmuio1-supply = <&vcc3v0_pmu>;
            pmuio2-supply = <&vcc3v0_pmu>;
        };
        reboot_mode: reboot-mode {
            compatible = "syscon-reboot-mode";
            offset = <512>;
            mode-bootloader = <1380107009>;
            mode-fastboot = <1380107017>;
            mode-loader = <1380107009>;
            mode-normal = <1380107008>;
            mode-recovery = <1380107011>;
            mode-charge = <1380107019>;
        };
        pmu_pvtm: pmu-pvtm {
            compatible = "rockchip,px30-pmu-pvtm";
            #address-cells = <1>;
            #size-cells = <0>;
            status = "okay";
            pvtm@1 {
                reg = <0x1>;
                clocks = <&pmucru 7>;
                clock-names = "clk";
            };
        };
    };
    uart0: serial@ff030000 {
        compatible = "rockchip,px30-uart", "snps,dw-apb-uart";
        reg = <0x0 0xff030000 0 0x100>;
        interrupts = <GIC_SPI 15 IRQ_TYPE_LEVEL_HIGH>;
        clocks = <&pmucru 6>, <&pmucru 21>;
        clock-names = "baudclk", "apb_pclk";
        dmas = <&dmac 0>, <&dmac 1>;
        reg-shift = <2>;
        reg-io-width = <4>;
        pinctrl-names = "default";
        pinctrl-0 = <&uart0_xfer &uart0_cts &uart0_rts>;
        status = "disabled";
    };
    i2s0_8ch: i2s@ff060000 {
        compatible = "rockchip,px30-i2s-tdm";
        reg = <0x0 0xff060000 0 0x1000>;
        interrupts = <GIC_SPI 12 IRQ_TYPE_LEVEL_HIGH>;
        clocks = <&cru 16>, <&cru 18>, <&cru 262>;
        clock-names = "mclk_tx", "mclk_rx", "hclk";
        dmas = <&dmac 16>, <&dmac 17>;
        dma-names = "tx", "rx";
        resets = <&cru 132>, <&cru 191>;
        reset-names = "tx-m", "rx-m";
        rockchip,cru = <2>;
        rockchip,grf = <&grf>;
        pinctrl-names = "default";
        pinctrl-0 = <&i2s0_8ch_sclktx &i2s0_8ch_sclkrx &i2s0_8ch_lrcktx &i2s0_8ch_lrckrx &i2s0_8ch_sdi0>, <&i2s0_8ch_sdi1 &i2s0_8ch_sdi2 &i2s0_8ch_sdi3 &i2s0_8ch_sdo0 &i2s0_8ch_sdo1>, <&i2s0_8ch_sdo2 &i2s0_8ch_sdo3>;
        status = "disabled";
    };
    i2s1_2ch: i2s@ff070000 {
        compatible = "rockchip,px30-i2s", "rockchip,rk3066-i2s";
        reg = <0x0 0xff070000 0 0x1000>;
        interrupts = <GIC_SPI 13 IRQ_TYPE_LEVEL_HIGH>;
        clocks = <&cru 20>, <&cru 263>;
        clock-names = "i2s_clk", "i2s_hclk";
        dmas = <&dmac 18>, <&dmac 19>;
        dma-names = "tx", "rx";
        pinctrl-names = "default";
        pinctrl-0 = <&i2s1_2ch_sclk &i2s1_2ch_lrck &i2s1_2ch_sdi &i2s1_2ch_sdo>;
        #sound-dai-cells = <0>;
        status = "okay";
    };
    i2s2_2ch: i2s@ff080000 {
        compatible = "rockchip,px30-i2s", "rockchip,rk3066-i2s";
        reg = <0x0 0xff080000 0 0x1000>;
        interrupts = <GIC_SPI 14 IRQ_TYPE_LEVEL_HIGH>;
        clocks = <&cru 22>, <&cru 264>;
        clock-names = "i2s_clk", "i2s_hclk";
        dmas = <&dmac 20>, <&dmac 21>;
        dma-names = "tx", "rx";
        pinctrl-names = "default";
        pinctrl-0 = <&i2s2_2ch_sclk &i2s2_2ch_lrck &i2s2_2ch_sdi &i2s2_2ch_sdo>;
        #sound-dai-cells = <0>;
        status = "disabled";
    };
    pdm: pdm@ff0a0000 {
        compatible = "rockchip,px30-pdm";
        reg = <0x0 0xff0a0000 0 0x1000>;
        clocks = <&cru 15>, <&cru 261>;
        clock-names = "pdm_clk", "pdm_hclk";
        dmas = <&dmac 24>;
        dma-names = "rx";
        resets = <&cru 130>;
        reset-names = "pdm-m";
        pinctrl-names = "default";
        pinctrl-0 = <&pdm_clk0m0 &pdm_clk1 &pdm_sdi0m0 &pdm_sdi1 &pdm_sdi2>, <&pdm_sdi3>;
        status = "disabled";
    };
    crypto: crypto@ff0b0000 {
        compatible = "rockchip,px30-crypto";
        reg = <0x0 0xff0b0000 0 0x400>, <0x0 0xff0b0480 0 0x3b80>;
        interrupts = <GIC_SPI 82 IRQ_TYPE_LEVEL_HIGH>;
        clocks = <&cru 172>, <&cru 241>, <&cru 48>, <&cru 49>;
        clock-names = "aclk", "hclk", "sclk", "apb_pclk";
        resets = <&cru 116>;
        reset-names = "crypto-rst";
        status = "disabled";
    };
    rng: rng@ff0b0000 {
        compatible = "rockchip,cryptov2-rng";
        reg = <0x0 0xff0b0400 0 0x80>;
        clocks = <&cru 48>, <&cru 49>, <&cru 172>, <&cru 241>;
        clock-names = "clk_crypto", "clk_crypto_apk", "aclk_crypto", "hclk_crypto";
        assigned-clocks = <&cru 48>, <&cru 49>, <&cru 172>, <&cru 241>;
        assigned-clock-rates = <150000000 150000000 200000000 200000000>;
        resets = <&cru 116>;
        reset-names = "reset";
        status = "okay";
    };
    gic: interrupt-controller@ff131000 {
        compatible = "arm,gic-400";
        #interrupt-cells = <3>;
        #address-cells = <0>;
        interrupt-controller;
        reg = <0x0 0xff131000 0 0x1000>, <0x0 0xff132000 0 0x2000>, <0x0 0xff134000 0 0x2000>, <0x0 0xff136000 0 0x2000>;
        interrupts = <GIC_PPI 9 3844>;
    };
    grf: syscon@ff140000 {
        compatible = "rockchip,px30-grf", "syscon", "simple-mfd";
        reg = <0x0 0xff140000 0 0x1000>;
        #address-cells = <1>;
        #size-cells = <1>;
        io_domains: io-domains {
            compatible = "rockchip,px30-io-voltage-domain";
            status = "okay";
            vccio1-supply = <&vcc_3v0>;
            vccio2-supply = <&vccio_sd>;
            vccio3-supply = <&vcc_3v0>;
            vccio4-supply = <&vcc_3v0>;
            vccio5-supply = <&vcc_3v0>;
            vccio6-supply = <&vcc_3v0>;
        };
        lvds: lvds {
            compatible = "rockchip,px30-lvds";
            phys = <&dsi_dphy>;
            phy-names = "phy";
            status = "disabled";
            ports {
                #address-cells = <1>;
                #size-cells = <0>;
                port@0 {
                    reg = <0x0>;
                    #address-cells = <1>;
                    #size-cells = <0>;
                    lvds_vopb_in: endpoint@0 {
                        reg = <0x0>;
                        remote-endpoint = <&vopb_out_lvds>;
                    };
                };
            };
        };
        rgb: rgb {
            compatible = "rockchip,px30-rgb";
            pinctrl-names = "default", "sleep";
            pinctrl-0 = <&lcdc_m1_rgb_pins>;
            pinctrl-1 = <&lcdc_m1_sleep_pins>;
            status = "disabled";
            phys = <&dsi_dphy>;
            phy-names = "phy";
            ports {
                #address-cells = <1>;
                #size-cells = <0>;
                port@0 {
                    reg = <0x0>;
                    #address-cells = <1>;
                    #size-cells = <0>;
                    rgb_in_vopb: endpoint@0 {
                        reg = <0x0>;
                        remote-endpoint = <&vopb_out_rgb>;
                    };
                };
            };
        };
    };
    core_grf: syscon@ff148000 {
        compatible = "syscon", "simple-mfd";
        reg = <0x0 0xff148000 0 0x1000>;
        #address-cells = <1>;
        #size-cells = <1>;
        pvtm: pvtm {
            compatible = "rockchip,px30-pvtm";
            #address-cells = <1>;
            #size-cells = <0>;
            status = "okay";
            pvtm@0 {
                reg = <0x0>;
                clocks = <&cru 74>;
                clock-names = "clk";
            };
        };
    };
    uart1: serial@ff158000 {
        compatible = "rockchip,px30-uart", "snps,dw-apb-uart";
        reg = <0x0 0xff158000 0 0x100>;
        interrupts = <GIC_SPI 16 IRQ_TYPE_LEVEL_HIGH>;
        clocks = <&cru 24>, <&cru 329>;
        clock-names = "baudclk", "apb_pclk";
        dmas = <&dmac 2>, <&dmac 3>;
        reg-shift = <2>;
        reg-io-width = <4>;
        pinctrl-names = "default";
        pinctrl-0 = <&uart1_xfer &uart1_cts>;
        status = "okay";
    };
    uart2: serial@ff160000 {
        compatible = "rockchip,px30-uart", "snps,dw-apb-uart";
        reg = <0x0 0xff160000 0 0x100>;
        interrupts = <GIC_SPI 17 IRQ_TYPE_LEVEL_HIGH>;
        clocks = <&cru 25>, <&cru 330>;
        clock-names = "baudclk", "apb_pclk";
        dmas = <&dmac 4>, <&dmac 5>;
        reg-shift = <2>;
        reg-io-width = <4>;
        pinctrl-names = "default";
        pinctrl-0 = <&uart2m0_xfer>;
        status = "disabled";
    };
    uart3: serial@ff168000 {
        compatible = "rockchip,px30-uart", "snps,dw-apb-uart";
        reg = <0x0 0xff168000 0 0x100>;
        interrupts = <GIC_SPI 18 IRQ_TYPE_LEVEL_HIGH>;
        clocks = <&cru 26>, <&cru 331>;
        clock-names = "baudclk", "apb_pclk";
        dmas = <&dmac 6>, <&dmac 7>;
        reg-shift = <2>;
        reg-io-width = <4>;
        pinctrl-names = "default";
        pinctrl-0 = <&uart3m1_xfer &uart3m1_cts &uart3m1_rts>;
        status = "disabled";
    };
    uart4: serial@ff170000 {
        compatible = "rockchip,px30-uart", "snps,dw-apb-uart";
        reg = <0x0 0xff170000 0 0x100>;
        interrupts = <GIC_SPI 19 IRQ_TYPE_LEVEL_HIGH>;
        clocks = <&cru 27>, <&cru 332>;
        clock-names = "baudclk", "apb_pclk";
        dmas = <&dmac 8>, <&dmac 9>;
        reg-shift = <2>;
        reg-io-width = <4>;
        pinctrl-names = "default";
        pinctrl-0 = <&uart4_xfer &uart4_cts &uart4_rts>;
        status = "disabled";
    };
    uart5: serial@ff178000 {
        compatible = "rockchip,px30-uart", "snps,dw-apb-uart";
        reg = <0x0 0xff178000 0 0x100>;
        interrupts = <GIC_SPI 20 IRQ_TYPE_LEVEL_HIGH>;
        clocks = <&cru 28>, <&cru 333>;
        clock-names = "baudclk", "apb_pclk";
        dmas = <&dmac 10>, <&dmac 11>;
        reg-shift = <2>;
        reg-io-width = <4>;
        pinctrl-names = "default";
        pinctrl-0 = <&uart5_xfer &uart5_cts &uart5_rts>;
        status = "disabled";
    };
    i2c0: i2c@ff180000 {
        compatible = "rockchip,px30-i2c", "rockchip,rk3399-i2c";
        reg = <0x0 0xff180000 0 0x1000>;
        clocks = <&cru 29>, <&cru 334>;
        clock-names = "i2c", "pclk";
        interrupts = <GIC_SPI 7 IRQ_TYPE_LEVEL_HIGH>;
        pinctrl-names = "default";
        pinctrl-0 = <&i2c0_xfer>;
        #address-cells = <1>;
        #size-cells = <0>;
        status = "okay";
        clock-frequency = <400000>;
        i2c-scl-rising-time-ns = <280>;
        i2c-scl-falling-time-ns = <16>;
        rk817: pmic@20 {
            compatible = "rockchip,rk817";
            reg = <0x20>;
            interrupt-parent = <&gpio0>;
            interrupts = <10 8>;
            pinctrl-names = "default", "pmic-sleep", "pmic-power-off", "pmic-reset";
            pinctrl-0 = <&pmic_int>;
            pinctrl-1 = <&soc_slppin_slp &rk817_slppin_slp>;
            pinctrl-2 = <&soc_slppin_gpio &rk817_slppin_pwrdn>;
            pinctrl-3 = <&soc_slppin_rst &rk817_slppin_rst>;
            rockchip,system-power-controller;
            wakeup-source;
            #clock-cells = <1>;
            clock-output-names = "rk808-clkout1", "rk808-clkout2";
            pmic-reset-func = <1>;
            vcc1-supply = <&vccsys>;
            vcc2-supply = <&vccsys>;
            vcc3-supply = <&vccsys>;
            vcc4-supply = <&vccsys>;
            vcc5-supply = <&vccsys>;
            vcc6-supply = <&vccsys>;
            vcc7-supply = <&vccsys>;
            vcc8-supply = <&vccsys>;
            vcc9-supply = <&dcdc_boost>;
            pwrkey {
                status = "okay";
            };
            pinctrl_rk8xx: pinctrl_rk8xx {
                gpio-controller;
                #gpio-cells = <2>;
                rk817_ts_gpio1: rk817_ts_gpio1 {
                    pins = "gpio_ts";
                    function = "pin_fun1";
                };
                rk817_gt_gpio2: rk817_gt_gpio2 {
                    pins = "gpio_gt";
                    function = "pin_fun1";
                };
                rk817_pin_ts: rk817_pin_ts {
                    pins = "gpio_ts";
                    function = "pin_fun0";
                };
                rk817_pin_gt: rk817_pin_gt {
                    pins = "gpio_gt";
                    function = "pin_fun0";
                };
                rk817_slppin_null: rk817_slppin_null {
                    pins = "gpio_slp";
                    function = "pin_fun0";
                };
                rk817_slppin_slp: rk817_slppin_slp {
                    pins = "gpio_slp";
                    function = "pin_fun1";
                };
                rk817_slppin_pwrdn: rk817_slppin_pwrdn {
                    pins = "gpio_slp";
                    function = "pin_fun2";
                };
                rk817_slppin_rst: rk817_slppin_rst {
                    pins = "gpio_slp";
                    function = "pin_fun3";
                };
            };
            regulators {
                vdd_logic: DCDC_REG1 {
                    regulator-always-on;
                    regulator-boot-on;
                    regulator-min-microvolt = <850000>;
                    regulator-max-microvolt = <1350000>;
                    regulator-ramp-delay = <6001>;
                    regulator-initial-mode = <2>;
                    regulator-name = "vdd_logic";
                    regulator-state-mem {
                        regulator-on-in-suspend;
                        regulator-suspend-microvolt = <950000>;
                    };
                };
                vdd_arm: DCDC_REG2 {
                    regulator-always-on;
                    regulator-boot-on;
                    regulator-min-microvolt = <850000>;
                    regulator-max-microvolt = <1350000>;
                    regulator-ramp-delay = <6001>;
                    regulator-initial-mode = <2>;
                    regulator-name = "vdd_arm";
                    regulator-state-mem {
                        regulator-off-in-suspend;
                        regulator-suspend-microvolt = <950000>;
                    };
                };
                vcc_ddr: DCDC_REG3 {
                    regulator-always-on;
                    regulator-boot-on;
                    regulator-initial-mode = <2>;
                    regulator-name = "vcc_ddr";
                    regulator-state-mem {
                        regulator-on-in-suspend;
                    };
                };
                vcc_3v0: DCDC_REG4 {
                    regulator-always-on;
                    regulator-boot-on;
                    regulator-min-microvolt = <3000000>;
                    regulator-max-microvolt = <3000000>;
                    regulator-initial-mode = <2>;
                    regulator-name = "vcc_3v0";
                    regulator-state-mem {
                        regulator-off-in-suspend;
                        regulator-suspend-microvolt = <3000000>;
                    };
                };
                vcc_1v0: LDO_REG1 {
                    regulator-always-on;
                    regulator-boot-on;
                    regulator-min-microvolt = <1000000>;
                    regulator-max-microvolt = <1000000>;
                    regulator-name = "vcc_1v0";
                    regulator-state-mem {
                        regulator-off-in-suspend;
                        regulator-suspend-microvolt = <1000000>;
                    };
                };
                vcc1v8_soc: LDO_REG2 {
                    regulator-always-on;
                    regulator-boot-on;
                    regulator-min-microvolt = <1800000>;
                    regulator-max-microvolt = <1800000>;
                    regulator-name = "vcc1v8_soc";
                    regulator-state-mem {
                        regulator-on-in-suspend;
                        regulator-suspend-microvolt = <1800000>;
                    };
                };
                vdd1v0_soc: LDO_REG3 {
                    regulator-always-on;
                    regulator-boot-on;
                    regulator-min-microvolt = <1000000>;
                    regulator-max-microvolt = <1000000>;
                    regulator-name = "vcc1v0_soc";
                    regulator-state-mem {
                        regulator-on-in-suspend;
                        regulator-suspend-microvolt = <1000000>;
                    };
                };
                vcc3v0_pmu: LDO_REG4 {
                    regulator-always-on;
                    regulator-boot-on;
                    regulator-min-microvolt = <3000000>;
                    regulator-max-microvolt = <3000000>;
                    regulator-name = "vcc3v0_pmu";
                    regulator-state-mem {
                        regulator-on-in-suspend;
                        regulator-suspend-microvolt = <3000000>;
                    };
                };
                vccio_sd: LDO_REG5 {
                    regulator-always-on;
                    regulator-boot-on;
                    regulator-min-microvolt = <1800000>;
                    regulator-max-microvolt = <3300000>;
                    regulator-name = "vccio_sd";
                    regulator-state-mem {
                        regulator-off-in-suspend;
                        regulator-suspend-microvolt = <3300000>;
                    };
                };
                vcc_sd: LDO_REG6 {
                    regulator-min-microvolt = <3300000>;
                    regulator-max-microvolt = <3300000>;
                    regulator-boot-on;
                    regulator-name = "vcc_sd";
                    regulator-state-mem {
                        regulator-off-in-suspend;
                        regulator-suspend-microvolt = <3300000>;
                    };
                };
                dcdc_boost: BOOST {
                    regulator-always-on;
                    regulator-boot-on;
                    regulator-min-microvolt = <5000000>;
                    regulator-max-microvolt = <5000000>;
                    regulator-name = "boost";
                    regulator-state-mem {
                        regulator-off-in-suspend;
                    };
                };
                otg_switch: OTG_SWITCH {
                    regulator-name = "otg_switch";
                    regulator-state-mem {
                        regulator-off-in-suspend;
                    };
                };
            };
            battery {
                compatible = "rk817,battery";
                ocv_table = <3444 3643 3694 3708 3738 3754 3776 3790 3805 3826 3848 3878 3921 3967 4011 4062 4107 4163 4217 4276 4333>;
                design_capacity = <1730>;
                design_qmax = <1903>;
                bat_res = <111>;
                sleep_enter_current = <300>;
                sleep_exit_current = <300>;
                sleep_filter_current = <100>;
                power_off_thresd = <3400>;
                zero_algorithm_vol = <3950>;
                max_soc_offset = <60>;
                monitor_sec = <5>;
                virtual_power = <0>;
                sample_res = <10>;
            };
            charger {
                compatible = "rk817,charger";
                min_input_voltage = <4500>;
                max_input_current = <2000>;
                max_chrg_current = <2000>;
                max_chrg_voltage = <4350>;
                chrg_term_mode = <0>;
                chrg_finish_cur = <300>;
                virtual_power = <0>;
                sample_res = <10>;
                pinctrl-names = "default";
                pinctrl-0 = <&led_gpio>;
                avrman-charger-led0-gpio = <&gpio1 RK_PB2 GPIO_ACTIVE_HIGH>;
                avrman-charger-led1-gpio = <&gpio1 RK_PB4 GPIO_ACTIVE_HIGH>;
                avrman-charger-led2-gpio = <&gpio1 RK_PB5 GPIO_ACTIVE_HIGH>;
                avrman-charger-led3-gpio = <&gpio1 RK_PB6 GPIO_ACTIVE_HIGH>;
                avrman-charger-led4-gpio = <&gpio1 RK_PB7 GPIO_ACTIVE_HIGH>;
                extcon = <&u2phy>;
            };
            rk817_codec: codec {
                #sound-dai-cells = <0>;
                compatible = "rockchip,rk817-codec";
                clocks = <&cru 21>;
                clock-names = "mclk";
                pinctrl-names = "default", "hp_det_gpio";
                pinctrl-0 = <&i2s1_2ch_mclk>;
                pinctrl-1 = <&hp_det>;
                avrman-hp-det-gpio = <&gpio2 RK_PC6 GPIO_ACTIVE_HIGH>;
                hp-volume = <20>;
                spk-volume = <3>;
                status = "okay";
            };
        };
    };
    i2c1: i2c@ff190000 {
        compatible = "rockchip,px30-i2c", "rockchip,rk3399-i2c";
        reg = <0x0 0xff190000 0 0x1000>;
        clocks = <&cru 30>, <&cru 335>;
        clock-names = "i2c", "pclk";
        interrupts = <GIC_SPI 8 IRQ_TYPE_LEVEL_HIGH>;
        pinctrl-names = "default";
        pinctrl-0 = <&i2c1_xfer>;
        #address-cells = <1>;
        #size-cells = <0>;
        status = "disabled";
    };
    i2c2: i2c@ff1a0000 {
        compatible = "rockchip,px30-i2c", "rockchip,rk3399-i2c";
        reg = <0x0 0xff1a0000 0 0x1000>;
        clocks = <&cru 31>, <&cru 336>;
        clock-names = "i2c", "pclk";
        interrupts = <GIC_SPI 9 IRQ_TYPE_LEVEL_HIGH>;
        pinctrl-names = "default";
        pinctrl-0 = <&i2c2_xfer>;
        #address-cells = <1>;
        #size-cells = <0>;
        status = "okay";
        eeprom@50 {
            compatible = "24c02";
            reg = <0x50>;
            status = "okay";
            pinctrl-names = "default";
            pinctrl-0 = <&eeprom_wp_gpio>;
            wp-gpio = <&gpio2 RK_PB5 GPIO_ACTIVE_HIGH>;
        };
    };
    i2c3: i2c@ff1b0000 {
        compatible = "rockchip,px30-i2c", "rockchip,rk3399-i2c";
        reg = <0x0 0xff1b0000 0 0x1000>;
        clocks = <&cru 32>, <&cru 337>;
        clock-names = "i2c", "pclk";
        interrupts = <GIC_SPI 10 IRQ_TYPE_LEVEL_HIGH>;
        pinctrl-names = "default";
        pinctrl-0 = <&i2c3_xfer>;
        #address-cells = <1>;
        #size-cells = <0>;
        status = "disabled";
    };
    spi0: spi@ff1d0000 {
        compatible = "rockchip,px30-spi", "rockchip,rk3066-spi";
        reg = <0x0 0xff1d0000 0 0x1000>;
        interrupts = <GIC_SPI 26 IRQ_TYPE_LEVEL_HIGH>;
        clocks = <&cru 36>, <&cru 341>;
        clock-names = "spiclk", "apb_pclk";
        dmas = <&dmac 12>, <&dmac 13>;
        dma-names = "tx", "rx";
        pinctrl-names = "default";
        pinctrl-0 = <&spi0_clk &spi0_csn &spi0_miso &spi0_mosi>;
        #address-cells = <1>;
        #size-cells = <0>;
        status = "disabled";
    };
    spi1: spi@ff1d8000 {
        compatible = "rockchip,px30-spi", "rockchip,rk3066-spi";
        reg = <0x0 0xff1d8000 0 0x1000>;
        interrupts = <GIC_SPI 27 IRQ_TYPE_LEVEL_HIGH>;
        clocks = <&cru 37>, <&cru 342>;
        clock-names = "spiclk", "apb_pclk";
        dmas = <&dmac 14>, <&dmac 15>;
        dma-names = "tx", "rx";
        pinctrl-names = "default";
        pinctrl-0 = <&spi1_clk &spi1_csn0 &spi1_csn1 &spi1_miso &spi1_mosi>;
        #address-cells = <1>;
        #size-cells = <0>;
        status = "disabled";
    };
    wdt: watchdog@ff1e0000 {
        compatible = "snps,dw-wdt";
        reg = <0x0 0xff1e0000 0 0x100>;
        clocks = <&cru 347>;
        interrupts = <GIC_SPI 37 IRQ_TYPE_LEVEL_HIGH>;
        status = "disabled";
    };
    pwm0: pwm@ff200000 {
        compatible = "rockchip,px30-pwm", "rockchip,rk3328-pwm";
        reg = <0x0 0xff200000 0 0x10>;
        interrupts = <GIC_SPI 24 IRQ_TYPE_LEVEL_HIGH>;
        clocks = <&cru 34>, <&cru 339>;
        clock-names = "pwm", "pclk";
        pinctrl-names = "active";
        pinctrl-0 = <&pwm0_pin>;
        #pwm-cells = <3>;
        status = "okay";
    };
    pwm1: pwm@ff200010 {
        compatible = "rockchip,px30-pwm", "rockchip,rk3328-pwm";
        reg = <0x0 0xff200010 0 0x10>;
        interrupts = <GIC_SPI 24 IRQ_TYPE_LEVEL_HIGH>;
        clocks = <&cru 34>, <&cru 339>;
        clock-names = "pwm", "pclk";
        pinctrl-names = "active";
        pinctrl-0 = <&pwm1_pin>;
        #pwm-cells = <3>;
        status = "okay";
    };
    pwm2: pwm@ff200020 {
        compatible = "rockchip,px30-pwm", "rockchip,rk3328-pwm";
        reg = <0x0 0xff200020 0 0x10>;
        interrupts = <GIC_SPI 24 IRQ_TYPE_LEVEL_HIGH>;
        clocks = <&cru 34>, <&cru 339>;
        clock-names = "pwm", "pclk";
        pinctrl-names = "active";
        pinctrl-0 = <&pwm2_pin>;
        #pwm-cells = <3>;
        status = "disabled";
    };
    pwm3: pwm@ff200030 {
        compatible = "rockchip,px30-pwm", "rockchip,rk3328-pwm";
        reg = <0x0 0xff200030 0 0x10>;
        interrupts = <GIC_SPI 24 IRQ_TYPE_LEVEL_HIGH>, <GIC_SPI 89 IRQ_TYPE_LEVEL_HIGH>;
        clocks = <&cru 34>, <&cru 339>;
        clock-names = "pwm", "pclk";
        pinctrl-names = "active";
        pinctrl-0 = <&pwm3_pin>;
        #pwm-cells = <3>;
        status = "disabled";
    };
    pwm4: pwm@ff208000 {
        compatible = "rockchip,px30-pwm", "rockchip,rk3328-pwm";
        reg = <0x0 0xff208000 0 0x10>;
        interrupts = <GIC_SPI 25 IRQ_TYPE_LEVEL_HIGH>;
        clocks = <&cru 35>, <&cru 340>;
        clock-names = "pwm", "pclk";
        pinctrl-names = "active";
        pinctrl-0 = <&pwm4_pin>;
        #pwm-cells = <3>;
        status = "disabled";
    };
    pwm5: pwm@ff208010 {
        compatible = "rockchip,px30-pwm", "rockchip,rk3328-pwm";
        reg = <0x0 0xff208010 0 0x10>;
        interrupts = <GIC_SPI 25 IRQ_TYPE_LEVEL_HIGH>;
        clocks = <&cru 35>, <&cru 340>;
        clock-names = "pwm", "pclk";
        pinctrl-names = "active";
        pinctrl-0 = <&pwm5_pin>;
        #pwm-cells = <3>;
        status = "disabled";
    };
    pwm6: pwm@ff208020 {
        compatible = "rockchip,px30-pwm", "rockchip,rk3328-pwm";
        reg = <0x0 0xff208020 0 0x10>;
        interrupts = <GIC_SPI 25 IRQ_TYPE_LEVEL_HIGH>;
        clocks = <&cru 35>, <&cru 340>;
        clock-names = "pwm", "pclk";
        pinctrl-names = "active";
        pinctrl-0 = <&pwm6_pin>;
        #pwm-cells = <3>;
        status = "disabled";
    };
    pwm7: pwm@ff208030 {
        compatible = "rockchip,px30-pwm", "rockchip,rk3328-pwm";
        reg = <0x0 0xff208030 0 0x10>;
        interrupts = <GIC_SPI 25 IRQ_TYPE_LEVEL_HIGH>, <GIC_SPI 90 IRQ_TYPE_LEVEL_HIGH>;
        clocks = <&cru 35>, <&cru 340>;
        clock-names = "pwm", "pclk";
        pinctrl-names = "active";
        pinctrl-0 = <&pwm7_pin>;
        #pwm-cells = <3>;
        status = "disabled";
    };
    rktimer: timer@ff210000 {
        compatible = "rockchip,px30-timer", "rockchip,rk3288-timer";
        reg = <0x0 0xff210000 0 0x1000>;
        interrupts = <GIC_SPI 30 IRQ_TYPE_LEVEL_HIGH>;
        clocks = <&cru 345>, <&cru 38>;
        clock-names = "pclk", "timer";
    };
    amba: bus {
        compatible = "simple-bus";
        #address-cells = <2>;
        #size-cells = <2>;
        ranges;
        dmac: dmac@ff240000 {
            compatible = "arm,pl330", "arm,primecell";
            reg = <0x0 0xff240000 0 0x4000>;
            interrupts = <GIC_SPI 1 IRQ_TYPE_LEVEL_HIGH>, <GIC_SPI 2 IRQ_TYPE_LEVEL_HIGH>;
            arm,pl330-periph-burst;
            clocks = <&cru 187>;
            clock-names = "apb_pclk";
            #dma-cells = <1>;
        };
    };
    tsadc: tsadc@ff280000 {
        compatible = "rockchip,px30-tsadc";
        reg = <0x0 0xff280000 0 0x100>;
        interrupts = <GIC_SPI 36 IRQ_TYPE_LEVEL_HIGH>;
        assigned-clocks = <&cru 44>;
        assigned-clock-rates = <50000>;
        clocks = <&cru 44>, <&cru 344>;
        clock-names = "tsadc", "apb_pclk";
        resets = <&cru 168>;
        reset-names = "tsadc-apb";
        rockchip,grf = <&grf>;
        rockchip,hw-tshut-temp = <120000>;
        pinctrl-names = "gpio", "otpout";
        pinctrl-0 = <&tsadc_otp_pin>;
        pinctrl-1 = <&tsadc_otp_out>;
        pinctrl-2 = <&tsadc_otp_pin>;
        #thermal-sensor-cells = <1>;
        status = "okay";
    };
    saradc: saradc@ff288000 {
        compatible = "rockchip,px30-saradc", "rockchip,rk3399-saradc";
        reg = <0x0 0xff288000 0 0x100>;
        interrupts = <GIC_SPI 84 IRQ_TYPE_LEVEL_HIGH>;
        #io-channel-cells = <1>;
        clocks = <&cru 45>, <&cru 343>;
        clock-names = "saradc", "apb_pclk";
        resets = <&cru 165>;
        reset-names = "saradc-apb";
        status = "okay";
        vref-supply = <&vcc1v8_soc>;
    };
    otp: nvmem@ff290000 {
        compatible = "rockchip,px30-otp";
        reg = <0x0 0xff290000 0 0x4000>;
        clocks = <&cru 47>, <&cru 346>, <&cru 353>;
        clock-names = "otp", "apb_pclk", "phy";
        resets = <&cru 180>;
        reset-names = "phy";
        #address-cells = <1>;
        #size-cells = <1>;
        cpu_id: id@7 {
            reg = <0x7 0x10>;
        };
        cpu_leakage: cpu-leakage@17 {
            reg = <0x17 0x1>;
        };
        performance: performance@1e {
            reg = <0x1e 0x1>;
            bits = <4 3>;
        };
    };
    cru: clock-controller@ff2b0000 {
        compatible = "rockchip,px30-cru";
        reg = <0x0 0xff2b0000 0 0x1000>;
        rockchip,grf = <&grf>;
        #clock-cells = <1>;
        #reset-cells = <1>;
        assigned-clocks = <&cru 4>;
        assigned-clock-rates = <1040000000>;
    };
    pmucru: clock-controller@ff2bc000 {
        compatible = "rockchip,px30-pmucru";
        reg = <0x0 0xff2bc000 0 0x1000>;
        rockchip,grf = <&grf>;
        #clock-cells = <1>;
        #reset-cells = <1>;
        assigned-clocks = <&pmucru 1>, <&pmucru 8>, <&pmucru 5>, <&cru 7>, <&cru 171>, <&cru 176>, <&cru 240>, <&cru 245>, <&cru 320>, <&cru 73>;
        assigned-clock-rates = <1200000000 100000000 26000000 600000000 200000000 200000000 150000000 150000000 100000000 200000000>;
    };
    usb2phy_grf: syscon@ff2c0000 {
        compatible = "rockchip,px30-usb2phy-grf", "syscon", "simple-mfd";
        reg = <0x0 0xff2c0000 0 0x10000>;
        #address-cells = <1>;
        #size-cells = <1>;
        u2phy: usb2-phy@100 {
            compatible = "rockchip,px30-usb2phy";
            reg = <0x100 0x20>;
            clocks = <&pmucru 10>;
            clock-names = "phyclk";
            #clock-cells = <0>;
            assigned-clocks = <&cru 14>, <&cru 85>;
            assigned-clock-parents = <&u2phy 2 14>;
            clock-output-names = "usb480m_phy";
            status = "okay";
            u2phy_host: host-port {
                #phy-cells = <0>;
                interrupts = <GIC_SPI 68 IRQ_TYPE_LEVEL_HIGH>;
                interrupt-names = "linestate";
                status = "okay";
            };
            u2phy_otg: otg-port {
                #phy-cells = <0>;
                interrupts = <GIC_SPI 66 IRQ_TYPE_LEVEL_HIGH>, <GIC_SPI 65 IRQ_TYPE_LEVEL_HIGH>, <GIC_SPI 64 IRQ_TYPE_LEVEL_HIGH>;
                interrupt-names = "otg-bvalid", "otg-id", "linestate";
                status = "okay";
            };
        };
    };
    dsi_dphy: phy@ff2e0000 {
        compatible = "rockchip,px30-dsi-dphy", "rockchip,px30-video-phy";
        reg = <0x0 0xff2e0000 0 0x10000>, <0x0 0xff450000 0 0x10000>;
        reg-names = "phy", "host";
        clocks = <&pmucru 11>, <&cru 325>, <&cru 324>;
        clock-names = "ref", "pclk", "pclk_host";
        resets = <&cru 62>;
        reset-names = "apb";
        #phy-cells = <0>;
        power-domains = <&power 12>;
        status = "okay";
    };
    mipi_dphy_rx0: mipi-dphy-rx0@ff2f0000 {
        compatible = "rockchip,rk3326-mipi-dphy";
        reg = <0x0 0xff2f0000 0 0x4000>;
        clocks = <&cru 326>;
        clock-names = "dphy-ref";
        power-domains = <&power 13>;
        rockchip,grf = <&grf>;
        status = "okay";
    };
    usb20_otg: usb@ff300000 {
        compatible = "rockchip,px30-usb", "rockchip,rk3066-usb", "snps,dwc2";
        reg = <0x0 0xff300000 0 0x40000>;
        interrupts = <GIC_SPI 62 IRQ_TYPE_LEVEL_HIGH>;
        clocks = <&cru 258>;
        clock-names = "otg";
        dr_mode = "otg";
        g-np-tx-fifo-size = <16>;
        g-rx-fifo-size = <280>;
        g-tx-fifo-size = <256 128 128 64 32 16>;
        phys = <&u2phy_otg>;
        phy-names = "usb2-phy";
        power-domains = <&power 5>;
        status = "okay";
    };
    usb_host0_ehci: usb@ff340000 {
        compatible = "generic-ehci";
        reg = <0x0 0xff340000 0 0x10000>;
        interrupts = <GIC_SPI 60 IRQ_TYPE_LEVEL_HIGH>;
        clocks = <&cru 259>, <&u2phy>;
        clock-names = "usbhost", "utmi";
        phys = <&u2phy_host>;
        phy-names = "usb";
        power-domains = <&power 5>;
        status = "disabled";
    };
    usb_host0_ohci: usb@ff350000 {
        compatible = "generic-ohci";
        reg = <0x0 0xff350000 0 0x10000>;
        interrupts = <GIC_SPI 61 IRQ_TYPE_LEVEL_HIGH>;
        clocks = <&cru 259>, <&u2phy>;
        clock-names = "usbhost", "utmi";
        phys = <&u2phy_host>;
        phy-names = "usb";
        power-domains = <&power 5>;
        status = "disabled";
    };
    gmac: ethernet@ff360000 {
        compatible = "rockchip,px30-gmac";
        reg = <0x0 0xff360000 0 0x10000>;
        interrupts = <GIC_SPI 43 IRQ_TYPE_LEVEL_HIGH>;
        interrupt-names = "macirq";
        clocks = <&cru 62>, <&cru 63>, <&cru 63>, <&cru 64>, <&cru 65>, <&cru 178>, <&cru 323>, <&cru 76>;
        clock-names = "stmmaceth", "mac_clk_rx", "mac_clk_tx", "clk_mac_ref", "clk_mac_refout", "aclk_mac", "pclk_mac", "clk_mac_speed";
        rockchip,grf = <&grf>;
        phy-mode = "rmii";
        pinctrl-names = "default";
        pinctrl-0 = <&rmii_pins &mac_refclk_12ma>;
        power-domains = <&power 9>;
        resets = <&cru 94>;
        reset-names = "stmmaceth";
        status = "disabled";
    };
    sdmmc: dwmmc@ff370000 {
        compatible = "rockchip,px30-dw-mshc", "rockchip,rk3288-dw-mshc";
        reg = <0x0 0xff370000 0 0x4000>;
        interrupts = <GIC_SPI 54 IRQ_TYPE_LEVEL_HIGH>;
        clocks = <&cru 247>, <&cru 59>, <&cru 67>, <&cru 68>;
        clock-names = "biu", "ciu", "ciu-drive", "ciu-sample";
        bus-width = <4>;
        fifo-depth = <256>;
        max-frequency = <150000000>;
        pinctrl-names = "default";
        pinctrl-0 = <&sdmmc_clk &sdmmc_cmd &sdmmc_det &sdmmc_bus4>;
        power-domains = <&power 7>;
        status = "okay";
        cap-mmc-highspeed;
        cap-sd-highspeed;
        supports-sd;
        card-detect-delay = <800>;
        ignore-pm-notify;
        disable-wp;
        cd-gpios = <&gpio0 RK_PA3 GPIO_ACTIVE_LOW>;
        sd-uhs-sdr12;
        sd-uhs-sdr25;
        sd-uhs-sdr50;
        sd-uhs-sdr104;
        vqmmc-supply = <&vccio_sd>;
        vmmc-supply = <&vcc_sd>;
    };
    sdio: dwmmc@ff380000 {
        compatible = "rockchip,px30-dw-mshc", "rockchip,rk3288-dw-mshc";
        reg = <0x0 0xff380000 0 0x4000>;
        interrupts = <GIC_SPI 55 IRQ_TYPE_LEVEL_HIGH>;
        clocks = <&cru 255>, <&cru 56>, <&cru 69>, <&cru 70>;
        clock-names = "biu", "ciu", "ciu-drive", "ciu-sample";
        bus-width = <4>;
        fifo-depth = <256>;
        max-frequency = <150000000>;
        pinctrl-names = "default";
        pinctrl-0 = <&sdio_bus4 &sdio_cmd &sdio_clk>;
        power-domains = <&power 10>;
        status = "disabled";
    };
    emmc: dwmmc@ff390000 {
        compatible = "rockchip,px30-dw-mshc", "rockchip,rk3288-dw-mshc";
        reg = <0x0 0xff390000 0 0x4000>;
        interrupts = <GIC_SPI 53 IRQ_TYPE_LEVEL_HIGH>;
        clocks = <&cru 256>, <&cru 57>, <&cru 71>, <&cru 72>;
        clock-names = "biu", "ciu", "ciu-drive", "ciu-sample";
        bus-width = <8>;
        fifo-depth = <256>;
        max-frequency = <150000000>;
        pinctrl-names = "default";
        pinctrl-0 = <&emmc_clk &emmc_cmd &emmc_bus8>;
        power-domains = <&power 10>;
        status = "disabled";
    };
    sfc: spi@ff3a0000 {
        compatible = "rockchip,sfc";
        reg = <0x0 0xff3a0000 0 0x4000>;
        interrupts = <GIC_SPI 56 IRQ_TYPE_LEVEL_HIGH>;
        clocks = <&cru 58>, <&cru 257>;
        clock-names = "clk_sfc", "hclk_sfc";
        assigned-clocks = <&cru 58>;
        assigned-clock-rates = <100000000>;
        status = "disabled";
    };
    nandc0: nandc@ff3b0000 {
        compatible = "rockchip,rk-nandc";
        reg = <0x0 0xff3b0000 0 0x4000>;
        interrupts = <GIC_SPI 57 IRQ_TYPE_LEVEL_HIGH>;
        nandc_id = <0>;
        clocks = <&cru 55>, <&cru 254>;
        clock-names = "clk_nandc", "hclk_nandc";
        assigned-clocks = <&cru 55>;
        assigned-clock-parents = <&cru 79>;
        power-domains = <&power 10>;
        status = "disabled";
    };
    gpu: gpu@ff400000 {
        compatible = "rockchip,px30-mali", "arm,mali-bifrost";
        reg = <0x0 0xff400000 0 0x4000>;
        interrupts = <GIC_SPI 45 IRQ_TYPE_LEVEL_HIGH>, <GIC_SPI 46 IRQ_TYPE_LEVEL_HIGH>, <GIC_SPI 47 IRQ_TYPE_LEVEL_HIGH>;
        interrupt-names = "gpu", "mmu", "job";
        clocks = <&cru 73>;
        #cooling-cells = <2>;
        power-domains = <&power 14>;
        operating-points-v2 = <&gpu_opp_table>;
        upthreshold = <40>;
        downdifferential = <10>;
        status = "okay";
        mali-supply = <&vdd_logic>;
        clock-names = "gpu", "bus";
        power_model {
            compatible = "arm,mali-simple-power-model";
            static-coefficient = <411000>;
            dynamic-coefficient = <733>;
            ts = <32000 4700 4294967216 2>;
            thermal-zone = "gpu-thermal";
        };
    };
    gpu_opp_table: gpu-opp-table {
        compatible = "operating-points-v2";
        rockchip,thermal-zone = "soc-thermal";
        rockchip,temp-hysteresis = <5000>;
        rockchip,low-temp = <0>;
        rockchip,low-temp-min-volt = <1000000>;
        rockchip,low-temp-adjust-volt = <0 480 50000>;
        rockchip,max-volt = <1175000>;
        rockchip,evb-irdrop = <25000>;
        rockchip,pvtm-voltage-sel = <0 50000 0 50001 54000 1 54001 60000 2 60001 99999 3>;
        rockchip,pvtm-ch = <0 0>;
        opp-200000000 {
            opp-hz = <0 200000000>;
            opp-microvolt = <950000>;
            opp-microvolt-L0 = <950000>;
            opp-microvolt-L1 = <950000>;
            opp-microvolt-L2 = <950000>;
            opp-microvolt-L3 = <950000>;
        };
        opp-300000000 {
            opp-hz = <0 300000000>;
            opp-microvolt = <975000>;
            opp-microvolt-L0 = <975000>;
            opp-microvolt-L1 = <950000>;
            opp-microvolt-L2 = <950000>;
            opp-microvolt-L3 = <950000>;
        };
        opp-400000000 {
            opp-hz = <0 400000000>;
            opp-microvolt = <1050000>;
            opp-microvolt-L0 = <1050000>;
            opp-microvolt-L1 = <1025000>;
            opp-microvolt-L2 = <975000>;
            opp-microvolt-L3 = <950000>;
        };
        opp-480000000 {
            opp-hz = <0 480000000>;
            opp-microvolt = <1125000>;
            opp-microvolt-L0 = <1125000>;
            opp-microvolt-L1 = <1100000>;
            opp-microvolt-L2 = <1050000>;
            opp-microvolt-L3 = <1000000>;
        };
        opp-520000000 {
            opp-hz = <0 520000000>;
            opp-microvolt = <1175000>;
            opp-microvolt-L0 = <1175000>;
            opp-microvolt-L1 = <1150000>;
            opp-microvolt-L2 = <1100000>;
            opp-microvolt-L3 = <1050000>;
        };
    };
    px30s_gpu_opp_table: px30s-gpu-opp-table {
        compatible = "operating-points-v2";
        rockchip,pvtm-voltage-sel = <0 69850 0 69851 73800 1 73801 77750 2 77751 81700 3 81701 99999 4>;
        rockchip,pvtm-ch = <0 0>;
        opp-200000000 {
            opp-hz = <0 200000000>;
            opp-microvolt = <950000>;
        };
        opp-300000000 {
            opp-hz = <0 300000000>;
            opp-microvolt = <950000>;
        };
        opp-400000000 {
            opp-hz = <0 400000000>;
            opp-microvolt = <950000>;
        };
        opp-520000000 {
            opp-hz = <0 520000000>;
            opp-microvolt = <1000000>;
            opp-microvolt-L0 = <1000000>;
            opp-microvolt-L1 = <975000>;
            opp-microvolt-L2 = <950000>;
            opp-microvolt-L3 = <950000>;
            opp-microvolt-L4 = <950000>;
        };
    };
    mpp_srv: mpp-srv {
        compatible = "rockchip,mpp-service";
        rockchip,taskqueue-count = <1>;
        rockchip,resetgroup-count = <1>;
        rockchip,grf = <&grf>;
        rockchip,grf-offset = <1040>;
        rockchip,grf-values = <2147516416 2147483648 2147483648>;
        rockchip,grf-names = "grf_rkvdec", "grf_vdpu2", "grf_vepu2";
        status = "okay";
    };
    vdpu: vdpu@ff442400 {
        compatible = "rockchip,vpu-decoder-px30";
        reg = <0x0 0xff442400 0 0x400>;
        interrupts = <GIC_SPI 79 IRQ_TYPE_LEVEL_HIGH>;
        interrupt-names = "irq_dec";
        clocks = <&cru 175>, <&cru 244>;
        clock-names = "aclk_vcodec", "hclk_vcodec";
        resets = <&cru 36>, <&cru 38>;
        reset-names = "shared_video_a", "shared_video_h";
        iommus = <&vpu_mmu>;
        power-domains = <&power 11>;
        rockchip,srv = <154>;
        rockchip,taskqueue-node = <0>;
        rockchip,resetgroup-node = <0>;
        status = "okay";
    };
    vpu_mmu: iommu@ff442800 {
        compatible = "rockchip,iommu";
        reg = <0x0 0xff442800 0 0x100>;
        interrupts = <GIC_SPI 81 IRQ_TYPE_LEVEL_HIGH>;
        interrupt-names = "vpu_mmu";
        clocks = <&cru 175>, <&cru 244>;
        clock-names = "aclk", "iface";
        power-domains = <&power 11>;
        rockchip,shootdown-entire;
        #iommu-cells = <0>;
        status = "okay";
    };
    vepu: vepu@ff442000 {
        compatible = "rockchip,vpu-encoder-px30";
        reg = <0x0 0xff442000 0 0x400>;
        interrupts = <GIC_SPI 80 IRQ_TYPE_LEVEL_HIGH>;
        interrupt-names = "irq_enc";
        clocks = <&cru 175>, <&cru 244>;
        clock-names = "aclk_vcodec", "hclk_vcodec";
        resets = <&cru 36>, <&cru 38>;
        reset-names = "shared_video_a", "shared_video_h";
        iommus = <&vpu_mmu>;
        power-domains = <&power 11>;
        rockchip,srv = <154>;
        rockchip,taskqueue-node = <0>;
        rockchip,resetgroup-node = <0>;
        status = "okay";
    };
    hevc: hevc@ff440000 {
        compatible = "rockchip,hevc-decoder-px30";
        reg = <0x0 0xff440000 0 0x400>;
        interrupts = <GIC_SPI 49 IRQ_TYPE_LEVEL_HIGH>;
        interrupt-names = "irq_dec";
        clocks = <&cru 175>, <&cru 244>, <&cru 75>;
        clock-names = "aclk_vcodec", "hclk_vcodec", "clk_core";
        resets = <&cru 36>, <&cru 38>, <&cru 37>, <&cru 39>, <&cru 63>;
        reset-names = "shared_video_a", "shared_video_h", "niu_a", "niu_h", "video_core";
        iommus = <&hevc_mmu>;
        rockchip,srv = <154>;
        rockchip,taskqueue-node = <0>;
        rockchip,resetgroup-node = <0>;
        power-domains = <&power 11>;
        status = "okay";
    };
    hevc_mmu: iommu@ff440440 {
        compatible = "rockchip,iommu";
        reg = <0x0 0xff440440 0 0x40>, <0x0 0xff440480 0 0x40>;
        interrupts = <GIC_SPI 50 IRQ_TYPE_LEVEL_HIGH>;
        interrupt-names = "hevc_mmu";
        clocks = <&cru 175>, <&cru 244>;
        clock-names = "aclk", "iface";
        power-domains = <&power 11>;
        rockchip,shootdown-entire;
        #iommu-cells = <0>;
        status = "okay";
    };
    dsi: dsi@ff450000 {
        compatible = "rockchip,px30-mipi-dsi";
        reg = <0x0 0xff450000 0 0x10000>;
        interrupts = <GIC_SPI 75 IRQ_TYPE_LEVEL_HIGH>;
        clocks = <&cru 324>;
        clock-names = "pclk";
        phys = <&dsi_dphy>;
        phy-names = "dphy";
        power-domains = <&power 12>;
        resets = <&cru 61>;
        reset-names = "apb";
        rockchip,grf = <&grf>;
        #address-cells = <1>;
        #size-cells = <0>;
        status = "okay";
        ports {
            #address-cells = <1>;
            #size-cells = <0>;
            port@0 {
                reg = <0x0>;
                #address-cells = <1>;
                #size-cells = <0>;
                dsi_in_vopb: endpoint@0 {
                    reg = <0x0>;
                    remote-endpoint = <&vopb_out_dsi>;
                    status = "okay";
                };
            };
            port@1 {
                reg = <0x1>;
                dsi_out_panel: endpoint {
                    remote-endpoint = <&panel_in_dsi>;
                };
            };
        };
        panel@0 {
            compatible = "sitronix,st7703", "simple-panel-dsi";
            reg = <0x0>;
            backlight = <&backlight>;
            power-supply = <&vcc_mipi_lcd0>;
            enable-gpios = <&gpio0 RK_PC1 GPIO_ACTIVE_HIGH>;
            reset-gpios = <&gpio0 RK_PB4 GPIO_ACTIVE_LOW>;
            pinctrl-names = "default";
            pinctrl-0 = <&dsi0_lcd_gpio>;
            rotation = <90>;
            prepare-delay-ms = <2>;
            reset-delay-ms = <1>;
            init-delay-ms = <20>;
            enable-delay-ms = <120>;
            disable-delay-ms = <50>;
            unprepare-delay-ms = <20>;
            width-mm = <68>;
            height-mm = <121>;
            dsi,flags = <2563>;
            dsi,format = <0>;
            dsi,lanes = <2>;
            panel-init-sequence = [39 00 06 FF 77 01 00 00 13 15 00 02 EF 08 39 00 06 FF 77 01 00 00 10 39 00 03 C0 4F 00 39 00 03 C1 10 0C 39 00 03 C2 01 14 15 00 02 CC 10 39 00 11 B0 00 0B 13 0D 10 07 02 08 07 1F 04 11 0F 28 2F 1F 39 00 11 B1 00 0C 13 0C 10 05 02 08 08 1E 05 13 11 27 30 1F 39 00 06 FF 77 01 00 00 11 15 00 02 B0 4D 15 00 02 B1 4D 15 00 02 B2 87 15 00 02 B3 80 15 00 02 B5 45 15 00 02 B7 85 15 00 02 B8 20 15 00 02 C0 09 15 00 02 C1 78 15 00 02 C2 78 15 64 02 D0 88 39 00 04 E0 00 00 02 39 00 0C E1 04 B0 06 B0 05 B0 07 B0 00 44 44 39 00 0D E2 20 20 44 44 96 A0 00 00 96 A0 00 00 39 00 05 E3 00 00 22 22 39 00 03 E4 44 44 39 00 11 E5 0C 90 B0 A0 0E 92 B0 A0 08 8C B0 A0 0A 8E B0 A0 39 00 05 E6 00 00 22 22 39 00 03 E7 44 44 39 00 11 E8 0D 91 B0 A0 0F 93 B0 A0 09 8D B0 A0 0B 8F B0 A0 39 00 03 E9 36 00 39 00 08 EB 00 00 E4 E4 44 88 40 39 00 11 ED C1 A2 BF 0F 67 45 FF FF FF FF 54 76 F0 FB 2A 1C 39 00 07 EF 10 0D 04 08 3F 1F 39 00 06 FF 77 01 00 00 13 39 00 03 E8 00 0E 39 00 06 FF 77 01 00 00 00 05 78 01 11 39 00 06 FF 77 01 00 00 13 39 0A 03 E8 00 0C 39 00 03 E8 00 00 39 00 06 FF 77 01 00 00 00 05 32 01 29];
            panel-exit-sequence = [05 00 01 28 05 00 01 10];
            display-timings {
                native-mode = <&timing0>;
                timing0: timing0 {
                    clock-frequency = <25000000>;
                    hactive = <480>;
                    vactive = <640>;
                    hfront-porch = <40>;
                    hsync-len = <10>;
                    hback-porch = <40>;
                    vfront-porch = <40>;
                    vsync-len = <10>;
                    vback-porch = <40>;
                    hsync-active = <0>;
                    vsync-active = <0>;
                    de-active = <0>;
                    pixelclk-active = <0>;
                };
            };
            ports {
                #address-cells = <1>;
                #size-cells = <0>;
                port@0 {
                    reg = <0x0>;
                    panel_in_dsi: endpoint {
                        remote-endpoint = <&dsi_out_panel>;
                    };
                };
            };
        };
    };
    vopb: vop@ff460000 {
        compatible = "rockchip,px30-vop-big";
        reg = <0x0 0xff460000 0 0x260>, <0x0 0xff460a00 0 0x400>;
        rockchip,grf = <&grf>;
        reg-names = "regs", "gamma_lut";
        interrupts = <GIC_SPI 77 IRQ_TYPE_LEVEL_HIGH>;
        clocks = <&cru 181>, <&cru 150>, <&cru 251>;
        clock-names = "aclk_vop", "dclk_vop", "hclk_vop";
        resets = <&cru 51>, <&cru 52>, <&cru 53>;
        reset-names = "axi", "ahb", "dclk";
        iommus = <&vopb_mmu>;
        power-domains = <&power 12>;
        status = "okay";
        vopb_out: port {
            #address-cells = <1>;
            #size-cells = <0>;
            vopb_out_dsi: endpoint@0 {
                reg = <0x0>;
                remote-endpoint = <&dsi_in_vopb>;
            };
            vopb_out_lvds: endpoint@1 {
                reg = <0x1>;
                remote-endpoint = <&lvds_vopb_in>;
            };
            vopb_out_rgb: endpoint@2 {
                reg = <0x2>;
                remote-endpoint = <&rgb_in_vopb>;
            };
        };
    };
    vopb_mmu: iommu@ff460f00 {
        compatible = "rockchip,iommu";
        reg = <0x0 0xff460f00 0 0x100>;
        interrupts = <GIC_SPI 77 IRQ_TYPE_LEVEL_HIGH>;
        interrupt-names = "vopb_mmu";
        clocks = <&cru 181>, <&cru 251>;
        clock-names = "aclk", "iface";
        power-domains = <&power 12>;
        #iommu-cells = <0>;
        rockchip,disable-device-link-resume;
        status = "okay";
    };
    rk_rga: rk_rga@ff480000 {
        compatible = "rockchip,rga2";
        reg = <0x0 0xff480000 0 0x1000>;
        interrupts = <GIC_SPI 76 IRQ_TYPE_LEVEL_HIGH>;
        clocks = <&cru 183>, <&cru 253>, <&cru 53>;
        clock-names = "aclk_rga", "hclk_rga", "clk_rga";
        power-domains = <&power 12>;
        status = "okay";
    };
    cif: cif@ff490000 {
        compatible = "rockchip,cif";
        reg = <0x0 0xff490000 0 0x200>;
        interrupts = <GIC_SPI 69 IRQ_TYPE_LEVEL_HIGH>;
        clocks = <&cru 179>, <&cru 249>, <&cru 352>, <&cru 52>;
        clock-names = "aclk_cif0", "hclk_cif0", "pclk_cif", "cif0_out";
        resets = <&cru 44>, <&cru 45>, <&cru 46>;
        reset-names = "rst_cif_a", "rst_cif_h", "rst_cif_pclkin";
        power-domains = <&power 13>;
        pinctrl-names = "cif_pin_all";
        pinctrl-0 = <&dvp_d2d9_m0>;
        iommus = <&vip_mmu>;
        status = "disabled";
    };
    cif_new: cif-new@ff490000 {
        compatible = "rockchip,px30-cif";
        reg = <0x0 0xff490000 0 0x200>;
        interrupts = <GIC_SPI 69 IRQ_TYPE_LEVEL_HIGH>;
        clocks = <&cru 179>, <&cru 249>, <&cru 352>, <&cru 52>;
        clock-names = "aclk_cif", "hclk_cif", "pclk_cif", "cif_out";
        resets = <&cru 44>, <&cru 45>, <&cru 46>;
        reset-names = "rst_cif_a", "rst_cif_h", "rst_cif_pclkin";
        power-domains = <&power 13>;
        iommus = <&vip_mmu>;
        status = "disabled";
    };
    vip_mmu: iommu@ff490800 {
        compatible = "rockchip,iommu";
        reg = <0x0 0xff490800 0 0x100>;
        interrupts = <GIC_SPI 69 IRQ_TYPE_LEVEL_HIGH>;
        interrupt-names = "vip_mmu";
        clocks = <&cru 179>, <&cru 249>;
        clock-names = "aclk", "iface";
        power-domains = <&power 13>;
        rk_iommu,disable_reset_quirk;
        #iommu-cells = <0>;
        status = "okay";
    };
    rk_isp: rk_isp@ff4a0000 {
        compatible = "rockchip,px30-isp", "rockchip,isp";
        reg = <0x0 0xff4a0000 0 0x8000>;
        interrupts = <GIC_SPI 70 IRQ_TYPE_LEVEL_HIGH>;
        clocks = <&cru 180>, <&cru 250>, <&cru 51>, <&cru 51>, <&cru 351>, <&cru 52>, <&cru 52>, <&cru 326>;
        clock-names = "aclk_isp", "hclk_isp", "clk_isp", "clk_isp_jpe", "pclkin_isp", "clk_cif_pll", "clk_cif_out", "pclk_dphyrx";
        resets = <&cru 43>, <&cru 47>;
        reset-names = "rst_isp", "rst_mipicsiphy";
        power-domains = <&power 13>;
        pinctrl-names = "default", "isp_dvp8bit2", "isp_dvp10bit", "isp_dvp12bit";
        pinctrl-0 = <&cif_clkout_m0>;
        pinctrl-1 = <&dvp_d2d9_m0>;
        pinctrl-2 = <&dvp_d2d9_m0 &dvp_d10d11_m0>;
        pinctrl-3 = <&dvp_d0d1_m0 &dvp_d2d9_m0 &dvp_d10d11_m0>;
        rockchip,isp,mipiphy = <1>;
        rockchip,isp,csiphy,reg = <4281270272 16384>;
        rockchip,grf = <&grf>;
        rockchip,cru = <2>;
        rockchip,isp,iommu-enable = <1>;
        iommus = <&isp_mmu>;
        status = "disabled";
    };
    rkisp1: rkisp1@ff4a0000 {
        compatible = "rockchip,rk3326-rkisp1";
        reg = <0x0 0xff4a0000 0 0x8000>;
        interrupts = <GIC_SPI 70 IRQ_TYPE_LEVEL_HIGH>, <GIC_SPI 73 IRQ_TYPE_LEVEL_HIGH>, <GIC_SPI 74 IRQ_TYPE_LEVEL_HIGH>;
        interrupt-names = "isp_irq", "mi_irq", "mipi_irq";
        clocks = <&cru 180>, <&cru 250>, <&cru 51>, <&cru 351>;
        clock-names = "aclk_isp", "hclk_isp", "clk_isp", "pclk_isp";
        devfreq = <&dmc>;
        power-domains = <&power 13>;
        iommus = <&isp_mmu>;
        rockchip,grf = <&grf>;
        status = "okay";
    };
    isp_mmu: iommu@ff4a8000 {
        compatible = "rockchip,iommu";
        reg = <0x0 0xff4a8000 0 0x100>;
        interrupts = <GIC_SPI 70 IRQ_TYPE_LEVEL_HIGH>;
        interrupt-names = "isp_mmu";
        clocks = <&cru 180>, <&cru 250>;
        clock-names = "aclk", "iface";
        power-domains = <&power 13>;
        rk_iommu,disable_reset_quirk;
        #iommu-cells = <0>;
        status = "okay";
    };
    qos_gmac: qos@ff518000 {
        compatible = "syscon";
        reg = <0x0 0xff518000 0 0x20>;
    };
    qos_gpu: qos@ff520000 {
        compatible = "syscon";
        reg = <0x0 0xff520000 0 0x20>;
    };
    qos_sdmmc: qos@ff52c000 {
        compatible = "syscon";
        reg = <0x0 0xff52c000 0 0x20>;
    };
    qos_emmc: qos@ff538000 {
        compatible = "syscon";
        reg = <0x0 0xff538000 0 0x20>;
    };
    qos_nand: qos@ff538080 {
        compatible = "syscon";
        reg = <0x0 0xff538080 0 0x20>;
    };
    qos_sdio: qos@ff538100 {
        compatible = "syscon";
        reg = <0x0 0xff538100 0 0x20>;
    };
    qos_sfc: qos@ff538180 {
        compatible = "syscon";
        reg = <0x0 0xff538180 0 0x20>;
    };
    qos_usb_host: qos@ff540000 {
        compatible = "syscon";
        reg = <0x0 0xff540000 0 0x20>;
    };
    qos_usb_otg: qos@ff540080 {
        compatible = "syscon";
        reg = <0x0 0xff540080 0 0x20>;
    };
    qos_isp_128: qos@ff548000 {
        compatible = "syscon";
        reg = <0x0 0xff548000 0 0x20>;
    };
    qos_isp_rd: qos@ff548080 {
        compatible = "syscon";
        reg = <0x0 0xff548080 0 0x20>;
    };
    qos_isp_wr: qos@ff548100 {
        compatible = "syscon";
        reg = <0x0 0xff548100 0 0x20>;
    };
    qos_isp_m1: qos@ff548180 {
        compatible = "syscon";
        reg = <0x0 0xff548180 0 0x20>;
    };
    qos_vip: qos@ff548200 {
        compatible = "syscon";
        reg = <0x0 0xff548200 0 0x20>;
    };
    qos_rga_rd: qos@ff550000 {
        compatible = "syscon";
        reg = <0x0 0xff550000 0 0x20>;
    };
    qos_rga_wr: qos@ff550080 {
        compatible = "syscon";
        reg = <0x0 0xff550080 0 0x20>;
    };
    qos_vop_m0: qos@ff550100 {
        compatible = "syscon";
        reg = <0x0 0xff550100 0 0x20>;
    };
    qos_vop_m1: qos@ff550180 {
        compatible = "syscon";
        reg = <0x0 0xff550180 0 0x20>;
    };
    qos_vpu: qos@ff558000 {
        compatible = "syscon";
        reg = <0x0 0xff558000 0 0x20>;
    };
    qos_vpu_r128: qos@ff558080 {
        compatible = "syscon";
        reg = <0x0 0xff558080 0 0x20>;
    };
    dfi: dfi@ff610000 {
        reg = <0x0 0xff610000 0 0x400>;
        compatible = "rockchip,px30-dfi";
        rockchip,pmugrf = <&pmugrf>;
        status = "okay";
    };
    dmc: dmc {
        compatible = "rockchip,px30-dmc";
        interrupts = <GIC_SPI 105 IRQ_TYPE_LEVEL_HIGH>;
        interrupt-names = "complete_irq";
        devfreq-events = <&dfi>;
        clocks = <&cru 84>;
        clock-names = "dmc_clk";
        operating-points-v2 = <&dmc_opp_table>;
        ddr_timing = <176>;
        upthreshold = <40>;
        downdifferential = <20>;
        system-status-freq = <1 666000 8 450000 2 194000 32 450000 4096 666000 16384 666000 8192 1056000>;
        auto-min-freq = <328000>;
        auto-freq-en = <1>;
        #cooling-cells = <2>;
        status = "okay";
        center-supply = <&vdd_logic>;
        ddr_power_model: ddr_power_model {
            compatible = "ddr_power_model";
            dynamic-power-coefficient = <120>;
            static-power-coefficient = <200>;
            ts = <32000 4700 4294967216 2>;
            thermal-zone = "soc-thermal";
        };
    };
    dmc_fsp: dmc-fsp {
        compatible = "rockchip,px30s-dmc-fsp";
        debug_print_level = <0>;
        phy_de_skew_en = <1>;
        ddr3_params = <177>;
        ddr4_params = <178>;
        lpddr2_params = <179>;
        lpddr3_params = <180>;
        lpddr4_params = <181>;
        ddr_timing = <176>;
        status = "okay";
    };
    dmc_opp_table: dmc-opp-table {
        compatible = "operating-points-v2";
        rockchip,max-volt = <1150000>;
        rockchip,evb-irdrop = <25000>;
        rockchip,pvtm-voltage-sel = <0 50000 0 50001 54000 1 54001 60000 2 60001 99999 3>;
        rockchip,pvtm-ch = <0 0>;
        opp-194000000 {
            opp-hz = <0 194000000>;
            opp-microvolt = <950000>;
            opp-microvolt-L0 = <950000>;
            opp-microvolt-L1 = <950000>;
            opp-microvolt-L2 = <950000>;
            opp-microvolt-L3 = <950000>;
        };
        opp-328000000 {
            opp-hz = <0 328000000>;
            opp-microvolt = <950000>;
            opp-microvolt-L0 = <950000>;
            opp-microvolt-L1 = <950000>;
            opp-microvolt-L2 = <950000>;
            opp-microvolt-L3 = <950000>;
        };
        opp-450000000 {
            opp-hz = <0 450000000>;
            opp-microvolt = <950000>;
            opp-microvolt-L0 = <950000>;
            opp-microvolt-L1 = <950000>;
            opp-microvolt-L2 = <950000>;
            opp-microvolt-L3 = <950000>;
        };
        opp-666000000 {
            opp-hz = <0 666000000>;
            opp-microvolt = <1050000>;
            opp-microvolt-L0 = <1050000>;
            opp-microvolt-L1 = <1000000>;
            opp-microvolt-L2 = <975000>;
            opp-microvolt-L3 = <950000>;
        };
        opp-786000000 {
            opp-hz = <0 786000000>;
            opp-microvolt = <1100000>;
            opp-microvolt-L0 = <1100000>;
            opp-microvolt-L1 = <1050000>;
            opp-microvolt-L2 = <1025000>;
            opp-microvolt-L3 = <1000000>;
            status = "disabled";
        };
    };
    px30s_dmc_opp_table: px30s-dmc-opp-table {
        compatible = "operating-points-v2";
        opp-194000000 {
            opp-hz = <0 194000000>;
            opp-microvolt = <950000>;
        };
        opp-328000000 {
            opp-hz = <0 328000000>;
            opp-microvolt = <950000>;
        };
        opp-666000000 {
            opp-hz = <0 666000000>;
            opp-microvolt = <950000>;
            status = "disabled";
        };
        opp-786000000 {
            opp-hz = <0 786000000>;
            opp-microvolt = <950000>;
            status = "disabled";
        };
        opp-924000000 {
            opp-hz = <0 924000000>;
            opp-microvolt = <950000>;
            status = "disabled";
        };
        opp-1056000000 {
            opp-hz = <0 1056000000>;
            opp-microvolt = <950000>;
        };
    };
    dmcdbg: dmcdbg {
        compatible = "rockchip,px30-dmcdbg";
        status = "okay";
    };
    rockchip_system_monitor: rockchip-system-monitor {
        compatible = "rockchip,system-monitor";
        rockchip,thermal-zone = "soc-thermal";
        rockchip,polling-delay = <200>;
    };
    pinctrl: pinctrl {
        compatible = "rockchip,px30-pinctrl";
        rockchip,grf = <&grf>;
        rockchip,pmu = <&pmugrf>;
        #address-cells = <2>;
        #size-cells = <2>;
        ranges;
        gpio0: gpio0@ff040000 {
            compatible = "rockchip,gpio-bank";
            reg = <0x0 0xff040000 0 0x100>;
            interrupts = <GIC_SPI 3 IRQ_TYPE_LEVEL_HIGH>;
            clocks = <&pmucru 20>;
            gpio-controller;
            #gpio-cells = <2>;
            interrupt-controller;
            #interrupt-cells = <2>;
        };
        gpio1: gpio1@ff250000 {
            compatible = "rockchip,gpio-bank";
            reg = <0x0 0xff250000 0 0x100>;
            interrupts = <GIC_SPI 4 IRQ_TYPE_LEVEL_HIGH>;
            clocks = <&cru 348>;
            gpio-controller;
            #gpio-cells = <2>;
            interrupt-controller;
            #interrupt-cells = <2>;
        };
        gpio2: gpio2@ff260000 {
            compatible = "rockchip,gpio-bank";
            reg = <0x0 0xff260000 0 0x100>;
            interrupts = <GIC_SPI 5 IRQ_TYPE_LEVEL_HIGH>;
            clocks = <&cru 349>;
            gpio-controller;
            #gpio-cells = <2>;
            interrupt-controller;
            #interrupt-cells = <2>;
        };
        gpio3: gpio3@ff270000 {
            compatible = "rockchip,gpio-bank";
            reg = <0x0 0xff270000 0 0x100>;
            interrupts = <GIC_SPI 6 IRQ_TYPE_LEVEL_HIGH>;
            clocks = <&cru 350>;
            gpio-controller;
            #gpio-cells = <2>;
            interrupt-controller;
            #interrupt-cells = <2>;
        };
        pcfg_pull_up: pcfg-pull-up {
            bias-pull-up;
        };
        pcfg_pull_down: pcfg-pull-down {
            bias-pull-down;
        };
        pcfg_pull_none: pcfg-pull-none {
            bias-disable;
        };
        pcfg_pull_none_2ma: pcfg-pull-none-2ma {
            bias-disable;
            drive-strength = <2>;
        };
        pcfg_pull_up_2ma: pcfg-pull-up-2ma {
            bias-pull-up;
            drive-strength = <2>;
        };
        pcfg_pull_up_4ma: pcfg-pull-up-4ma {
            bias-pull-up;
            drive-strength = <4>;
        };
        pcfg_pull_none_4ma: pcfg-pull-none-4ma {
            bias-disable;
            drive-strength = <4>;
        };
        pcfg_pull_down_4ma: pcfg-pull-down-4ma {
            bias-pull-down;
            drive-strength = <4>;
        };
        pcfg_pull_none_8ma: pcfg-pull-none-8ma {
            bias-disable;
            drive-strength = <8>;
        };
        pcfg_pull_up_8ma: pcfg-pull-up-8ma {
            bias-pull-up;
            drive-strength = <8>;
        };
        pcfg_pull_none_12ma: pcfg-pull-none-12ma {
            bias-disable;
            drive-strength = <12>;
        };
        pcfg_pull_up_12ma: pcfg-pull-up-12ma {
            bias-pull-up;
            drive-strength = <12>;
        };
        pcfg_pull_none_smt: pcfg-pull-none-smt {
            bias-disable;
            input-schmitt-enable;
        };
        pcfg_output_high: pcfg-output-high {
            output-high;
        };
        pcfg_output_low: pcfg-output-low {
            output-low;
        };
        pcfg_input_high: pcfg-input-high {
            bias-pull-up;
            input-enable;
        };
        pcfg_input: pcfg-input {
            input-enable;
        };
        i2c0 {
            i2c0_xfer: i2c0-xfer {
                rockchip,pins = <0 RK_PB0 1 &pcfg_pull_none_smt>, <0 RK_PB1 1 &pcfg_pull_none_smt>;
            };
        };
        i2c1 {
            i2c1_xfer: i2c1-xfer {
                rockchip,pins = <0 RK_PC2 1 &pcfg_pull_none_smt>, <0 RK_PC3 1 &pcfg_pull_none_smt>;
            };
        };
        i2c2 {
            i2c2_xfer: i2c2-xfer {
                rockchip,pins = <2 RK_PB7 2 &pcfg_pull_none_smt>, <2 RK_PC0 2 &pcfg_pull_none_smt>;
            };
        };
        i2c3 {
            i2c3_xfer: i2c3-xfer {
                rockchip,pins = <1 RK_PB4 4 &pcfg_pull_none_smt>, <1 RK_PB5 4 &pcfg_pull_none_smt>;
            };
        };
        tsadc {
            tsadc_otp_pin: tsadc-otp-pin {
                rockchip,pins = <0 RK_PA6 RK_FUNC_GPIO &pcfg_pull_none>;
            };
            tsadc_otp_out: tsadc-otp-out {
                rockchip,pins = <0 RK_PA6 1 &pcfg_pull_none>;
            };
        };
        uart0 {
            uart0_xfer: uart0-xfer {
                rockchip,pins = <0 RK_PB2 1 &pcfg_pull_up>, <0 RK_PB3 1 &pcfg_pull_up>;
            };
            uart0_cts: uart0-cts {
                rockchip,pins = <0 RK_PB4 1 &pcfg_pull_none>;
            };
            uart0_rts: uart0-rts {
                rockchip,pins = <0 RK_PB5 1 &pcfg_pull_none>;
            };
        };
        uart1 {
            uart1_xfer: uart1-xfer {
                rockchip,pins = <1 RK_PC1 1 &pcfg_pull_up>, <1 RK_PC0 1 &pcfg_pull_up>;
            };
            uart1_cts: uart1-cts {
                rockchip,pins = <1 RK_PC2 1 &pcfg_pull_none>;
            };
            uart1_rts: uart1-rts {
                rockchip,pins = <1 RK_PC3 1 &pcfg_pull_none>;
            };
            uart1_rts_gpio: uart1-rts-gpio {
                rockchip,pins = <1 RK_PC3 RK_FUNC_GPIO &pcfg_pull_none>;
            };
        };
        uart2-m0 {
            uart2m0_xfer: uart2m0-xfer {
                rockchip,pins = <1 RK_PD2 2 &pcfg_pull_up>, <1 RK_PD3 2 &pcfg_pull_up>;
            };
        };
        uart2-m1 {
            uart2m1_xfer: uart2m1-xfer {
                rockchip,pins = <2 RK_PB4 2 &pcfg_pull_up>, <2 RK_PB6 2 &pcfg_pull_up>;
            };
        };
        uart3-m0 {
            uart3m0_xfer: uart3m0-xfer {
                rockchip,pins = <0 RK_PC0 2 &pcfg_pull_up>, <0 RK_PC1 2 &pcfg_pull_up>;
            };
            uart3m0_cts: uart3m0-cts {
                rockchip,pins = <0 RK_PC2 2 &pcfg_pull_none>;
            };
            uart3m0_rts: uart3m0-rts {
                rockchip,pins = <0 RK_PC3 2 &pcfg_pull_none>;
            };
        };
        uart3-m1 {
            uart3m1_xfer: uart3m1-xfer {
                rockchip,pins = <1 RK_PB6 2 &pcfg_pull_up>, <1 RK_PB7 2 &pcfg_pull_up>;
            };
            uart3m1_cts: uart3m1-cts {
                rockchip,pins = <1 RK_PB4 2 &pcfg_pull_none>;
            };
            uart3m1_rts: uart3m1-rts {
                rockchip,pins = <1 RK_PB5 2 &pcfg_pull_none>;
            };
        };
        uart4 {
            uart4_xfer: uart4-xfer {
                rockchip,pins = <1 RK_PD4 2 &pcfg_pull_up>, <1 RK_PD5 2 &pcfg_pull_up>;
            };
            uart4_cts: uart4-cts {
                rockchip,pins = <1 RK_PD6 2 &pcfg_pull_none>;
            };
            uart4_rts: uart4-rts {
                rockchip,pins = <1 RK_PD7 2 &pcfg_pull_none>;
            };
        };
        uart5 {
            uart5_xfer: uart5-xfer {
                rockchip,pins = <3 RK_PA2 4 &pcfg_pull_up>, <3 RK_PA1 4 &pcfg_pull_up>;
            };
            uart5_cts: uart5-cts {
                rockchip,pins = <3 RK_PA3 4 &pcfg_pull_none>;
            };
            uart5_rts: uart5-rts {
                rockchip,pins = <3 RK_PA5 4 &pcfg_pull_none>;
            };
        };
        spi0 {
            spi0_clk: spi0-clk {
                rockchip,pins = <1 RK_PB7 3 &pcfg_pull_up_4ma>;
            };
            spi0_csn: spi0-csn {
                rockchip,pins = <1 RK_PB6 3 &pcfg_pull_up_4ma>;
            };
            spi0_miso: spi0-miso {
                rockchip,pins = <1 RK_PB5 3 &pcfg_pull_up_4ma>;
            };
            spi0_mosi: spi0-mosi {
                rockchip,pins = <1 RK_PB4 3 &pcfg_pull_up_4ma>;
            };
            spi0_clk_hs: spi0-clk-hs {
                rockchip,pins = <1 RK_PB7 3 &pcfg_pull_up_8ma>;
            };
            spi0_miso_hs: spi0-miso-hs {
                rockchip,pins = <1 RK_PB5 3 &pcfg_pull_up_8ma>;
            };
            spi0_mosi_hs: spi0-mosi-hs {
                rockchip,pins = <1 RK_PB4 3 &pcfg_pull_up_8ma>;
            };
        };
        spi1 {
            spi1_clk: spi1-clk {
                rockchip,pins = <3 RK_PB7 4 &pcfg_pull_up_4ma>;
            };
            spi1_csn0: spi1-csn0 {
                rockchip,pins = <3 RK_PB1 4 &pcfg_pull_up_4ma>;
            };
            spi1_csn1: spi1-csn1 {
                rockchip,pins = <3 RK_PB2 2 &pcfg_pull_up_4ma>;
            };
            spi1_miso: spi1-miso {
                rockchip,pins = <3 RK_PB6 4 &pcfg_pull_up_4ma>;
            };
            spi1_mosi: spi1-mosi {
                rockchip,pins = <3 RK_PB4 4 &pcfg_pull_up_4ma>;
            };
            spi1_clk_hs: spi1-clk-hs {
                rockchip,pins = <3 RK_PB7 4 &pcfg_pull_up_8ma>;
            };
            spi1_miso_hs: spi1-miso-hs {
                rockchip,pins = <3 RK_PB6 4 &pcfg_pull_up_8ma>;
            };
            spi1_mosi_hs: spi1-mosi-hs {
                rockchip,pins = <3 RK_PB4 4 &pcfg_pull_up_8ma>;
            };
        };
        pdm {
            pdm_clk0m0: pdm-clk0m0 {
                rockchip,pins = <3 RK_PC6 2 &pcfg_pull_none>;
            };
            pdm_clk0m1: pdm-clk0m1 {
                rockchip,pins = <2 RK_PC6 1 &pcfg_pull_none>;
            };
            pdm_clk1: pdm-clk1 {
                rockchip,pins = <3 RK_PC7 2 &pcfg_pull_none>;
            };
            pdm_sdi0m0: pdm-sdi0m0 {
                rockchip,pins = <3 RK_PD3 2 &pcfg_pull_none>;
            };
            pdm_sdi0m1: pdm-sdi0m1 {
                rockchip,pins = <2 RK_PC5 2 &pcfg_pull_none>;
            };
            pdm_sdi1: pdm-sdi1 {
                rockchip,pins = <3 RK_PD0 2 &pcfg_pull_none>;
            };
            pdm_sdi2: pdm-sdi2 {
                rockchip,pins = <3 RK_PD1 2 &pcfg_pull_none>;
            };
            pdm_sdi3: pdm-sdi3 {
                rockchip,pins = <3 RK_PD2 2 &pcfg_pull_none>;
            };
            pdm_clk0m0_sleep: pdm-clk0m0-sleep {
                rockchip,pins = <3 RK_PC6 RK_FUNC_GPIO &pcfg_input_high>;
            };
            pdm_clk0m_sleep1: pdm-clk0m1-sleep {
                rockchip,pins = <2 RK_PC6 RK_FUNC_GPIO &pcfg_input_high>;
            };
            pdm_clk1_sleep: pdm-clk1-sleep {
                rockchip,pins = <3 RK_PC7 RK_FUNC_GPIO &pcfg_input_high>;
            };
            pdm_sdi0m0_sleep: pdm-sdi0m0-sleep {
                rockchip,pins = <3 RK_PD3 RK_FUNC_GPIO &pcfg_input_high>;
            };
            pdm_sdi0m1_sleep: pdm-sdi0m1-sleep {
                rockchip,pins = <2 RK_PC5 RK_FUNC_GPIO &pcfg_input_high>;
            };
            pdm_sdi1_sleep: pdm-sdi1-sleep {
                rockchip,pins = <3 RK_PD0 RK_FUNC_GPIO &pcfg_input_high>;
            };
            pdm_sdi2_sleep: pdm-sdi2-sleep {
                rockchip,pins = <3 RK_PD1 RK_FUNC_GPIO &pcfg_input_high>;
            };
            pdm_sdi3_sleep: pdm-sdi3-sleep {
                rockchip,pins = <3 RK_PD2 RK_FUNC_GPIO &pcfg_input_high>;
            };
        };
        i2s0 {
            i2s0_8ch_mclk: i2s0-8ch-mclk {
                rockchip,pins = <3 RK_PC1 2 &pcfg_pull_none_smt>;
            };
            i2s0_8ch_sclktx: i2s0-8ch-sclktx {
                rockchip,pins = <3 RK_PC3 2 &pcfg_pull_none_smt>;
            };
            i2s0_8ch_sclkrx: i2s0-8ch-sclkrx {
                rockchip,pins = <3 RK_PB4 2 &pcfg_pull_none_smt>;
            };
            i2s0_8ch_lrcktx: i2s0-8ch-lrcktx {
                rockchip,pins = <3 RK_PC2 2 &pcfg_pull_none_smt>;
            };
            i2s0_8ch_lrckrx: i2s0-8ch-lrckrx {
                rockchip,pins = <3 RK_PB5 2 &pcfg_pull_none_smt>;
            };
            i2s0_8ch_sdo0: i2s0-8ch-sdo0 {
                rockchip,pins = <3 RK_PC4 2 &pcfg_pull_none>;
            };
            i2s0_8ch_sdo1: i2s0-8ch-sdo1 {
                rockchip,pins = <3 RK_PC0 2 &pcfg_pull_none>;
            };
            i2s0_8ch_sdo2: i2s0-8ch-sdo2 {
                rockchip,pins = <3 RK_PB7 2 &pcfg_pull_none>;
            };
            i2s0_8ch_sdo3: i2s0-8ch-sdo3 {
                rockchip,pins = <3 RK_PB6 2 &pcfg_pull_none>;
            };
            i2s0_8ch_sdi0: i2s0-8ch-sdi0 {
                rockchip,pins = <3 RK_PC5 2 &pcfg_pull_none>;
            };
            i2s0_8ch_sdi1: i2s0-8ch-sdi1 {
                rockchip,pins = <3 RK_PB3 2 &pcfg_pull_none>;
            };
            i2s0_8ch_sdi2: i2s0-8ch-sdi2 {
                rockchip,pins = <3 RK_PB1 2 &pcfg_pull_none>;
            };
            i2s0_8ch_sdi3: i2s0-8ch-sdi3 {
                rockchip,pins = <3 RK_PB0 2 &pcfg_pull_none>;
            };
        };
        i2s1 {
            i2s1_2ch_mclk: i2s1-2ch-mclk {
                rockchip,pins = <2 RK_PC3 1 &pcfg_pull_none_smt>;
            };
            i2s1_2ch_sclk: i2s1-2ch-sclk {
                rockchip,pins = <2 RK_PC2 1 &pcfg_pull_none_smt>;
            };
            i2s1_2ch_lrck: i2s1-2ch-lrck {
                rockchip,pins = <2 RK_PC1 1 &pcfg_pull_none_smt>;
            };
            i2s1_2ch_sdi: i2s1-2ch-sdi {
                rockchip,pins = <2 RK_PC5 1 &pcfg_pull_none>;
            };
            i2s1_2ch_sdo: i2s1-2ch-sdo {
                rockchip,pins = <2 RK_PC4 1 &pcfg_pull_none>;
            };
        };
        i2s2 {
            i2s2_2ch_mclk: i2s2-2ch-mclk {
                rockchip,pins = <3 RK_PA1 2 &pcfg_pull_none_smt>;
            };
            i2s2_2ch_sclk: i2s2-2ch-sclk {
                rockchip,pins = <3 RK_PA2 2 &pcfg_pull_none_smt>;
            };
            i2s2_2ch_lrck: i2s2-2ch-lrck {
                rockchip,pins = <3 RK_PA3 2 &pcfg_pull_none_smt>;
            };
            i2s2_2ch_sdi: i2s2-2ch-sdi {
                rockchip,pins = <3 RK_PA5 2 &pcfg_pull_none>;
            };
            i2s2_2ch_sdo: i2s2-2ch-sdo {
                rockchip,pins = <3 RK_PA7 2 &pcfg_pull_none>;
            };
        };
        sdmmc {
            sdmmc_clk: sdmmc-clk {
                rockchip,pins = <1 RK_PD6 1 &pcfg_pull_none_8ma>;
            };
            sdmmc_cmd: sdmmc-cmd {
                rockchip,pins = <1 RK_PD7 1 &pcfg_pull_up_8ma>;
            };
            sdmmc_det: sdmmc-det {
                rockchip,pins = <0 RK_PA3 1 &pcfg_pull_up_8ma>;
            };
            sdmmc_bus1: sdmmc-bus1 {
                rockchip,pins = <1 RK_PD2 1 &pcfg_pull_up_8ma>;
            };
            sdmmc_bus4: sdmmc-bus4 {
                rockchip,pins = <1 RK_PD2 1 &pcfg_pull_up_8ma>, <1 RK_PD3 1 &pcfg_pull_up_8ma>, <1 RK_PD4 1 &pcfg_pull_up_8ma>, <1 RK_PD5 1 &pcfg_pull_up_8ma>;
            };
        };
        sdio {
            sdio_clk: sdio-clk {
                rockchip,pins = <1 RK_PC5 1 &pcfg_pull_none>;
            };
            sdio_cmd: sdio-cmd {
                rockchip,pins = <1 RK_PC4 1 &pcfg_pull_up>;
            };
            sdio_bus4: sdio-bus4 {
                rockchip,pins = <1 RK_PC6 1 &pcfg_pull_up>, <1 RK_PC7 1 &pcfg_pull_up>, <1 RK_PD0 1 &pcfg_pull_up>, <1 RK_PD1 1 &pcfg_pull_up>;
            };
        };
        emmc {
            emmc_clk: emmc-clk {
                rockchip,pins = <1 RK_PB1 2 &pcfg_pull_none_8_6ma>;
            };
            emmc_cmd: emmc-cmd {
                rockchip,pins = <1 RK_PB2 2 &pcfg_pull_up_8_6ma>;
            };
            emmc_rstnout: emmc-rstnout {
                rockchip,pins = <1 RK_PB3 2 &pcfg_pull_none>;
            };
            emmc_bus1: emmc-bus1 {
                rockchip,pins = <1 RK_PA0 2 &pcfg_pull_up_8_6ma>;
            };
            emmc_bus4: emmc-bus4 {
                rockchip,pins = <1 RK_PA0 2 &pcfg_pull_up_8_6ma>, <1 RK_PA1 2 &pcfg_pull_up_8_6ma>, <1 RK_PA2 2 &pcfg_pull_up_8_6ma>, <1 RK_PA3 2 &pcfg_pull_up_8_6ma>;
            };
            emmc_bus8: emmc-bus8 {
                rockchip,pins = <1 RK_PA0 2 &pcfg_pull_up_8_6ma>, <1 RK_PA1 2 &pcfg_pull_up_8_6ma>, <1 RK_PA2 2 &pcfg_pull_up_8_6ma>, <1 RK_PA3 2 &pcfg_pull_up_8_6ma>, <1 RK_PA4 2 &pcfg_pull_up_8_6ma>, <1 RK_PA5 2 &pcfg_pull_up_8_6ma>, <1 RK_PA6 2 &pcfg_pull_up_8_6ma>, <1 RK_PA7 2 &pcfg_pull_up_8_6ma>;
            };
            emmc_pwren: emmc-pwren {
                rockchip,pins = <1 RK_PB0 2 &pcfg_pull_none>;
            };
        };
        flash {
            flash_cs0: flash-cs0 {
                rockchip,pins = <1 RK_PB0 1 &pcfg_pull_none>;
            };
            flash_rdy: flash-rdy {
                rockchip,pins = <1 RK_PB1 1 &pcfg_pull_none>;
            };
            flash_dqs: flash-dqs {
                rockchip,pins = <1 RK_PB2 1 &pcfg_pull_none>;
            };
            flash_ale: flash-ale {
                rockchip,pins = <1 RK_PB3 1 &pcfg_pull_none>;
            };
            flash_cle: flash-cle {
                rockchip,pins = <1 RK_PB4 1 &pcfg_pull_none>;
            };
            flash_wrn: flash-wrn {
                rockchip,pins = <1 RK_PB5 1 &pcfg_pull_none>;
            };
            flash_csl: flash-csl {
                rockchip,pins = <1 RK_PB6 1 &pcfg_pull_none>;
            };
            flash_rdn: flash-rdn {
                rockchip,pins = <1 RK_PB7 1 &pcfg_pull_none>;
            };
            flash_bus8: flash-bus8 {
                rockchip,pins = <1 RK_PA0 1 &pcfg_pull_up_12ma>, <1 RK_PA1 1 &pcfg_pull_up_12ma>, <1 RK_PA2 1 &pcfg_pull_up_12ma>, <1 RK_PA3 1 &pcfg_pull_up_12ma>, <1 RK_PA4 1 &pcfg_pull_up_12ma>, <1 RK_PA5 1 &pcfg_pull_up_12ma>, <1 RK_PA6 1 &pcfg_pull_up_12ma>, <1 RK_PA7 1 &pcfg_pull_up_12ma>;
            };
        };
        lcdc {
            lcdc_m0_rgb_pins: lcdc-m0-rgb-pins {
                rockchip,pins = <3 RK_PA0 1 &pcfg_pull_none_8ma>, <3 RK_PA1 1 &pcfg_pull_none_8ma>, <3 RK_PA2 1 &pcfg_pull_none_8ma>, <3 RK_PA3 1 &pcfg_pull_none_8ma>, <3 RK_PA4 1 &pcfg_pull_none_8ma>, <3 RK_PA5 1 &pcfg_pull_none_8ma>, <3 RK_PA6 1 &pcfg_pull_none_8ma>, <3 RK_PA7 1 &pcfg_pull_none_8ma>, <3 RK_PB0 1 &pcfg_pull_none_8ma>, <3 RK_PB1 1 &pcfg_pull_none_8ma>, <3 RK_PB2 1 &pcfg_pull_none_8ma>, <3 RK_PB3 1 &pcfg_pull_none_8ma>, <3 RK_PB4 1 &pcfg_pull_none_8ma>, <3 RK_PB5 1 &pcfg_pull_none_8ma>, <3 RK_PB6 1 &pcfg_pull_none_8ma>, <3 RK_PB7 1 &pcfg_pull_none_8ma>, <3 RK_PC0 1 &pcfg_pull_none_8ma>, <3 RK_PC1 1 &pcfg_pull_none_8ma>, <3 RK_PC2 1 &pcfg_pull_none_8ma>, <3 RK_PC3 1 &pcfg_pull_none_8ma>, <3 RK_PC4 1 &pcfg_pull_none_8ma>, <3 RK_PC5 1 &pcfg_pull_none_8ma>, <3 RK_PC6 1 &pcfg_pull_none_8ma>, <3 RK_PC7 1 &pcfg_pull_none_8ma>, <3 RK_PD0 1 &pcfg_pull_none_8ma>, <3 RK_PD1 1 &pcfg_pull_none_8ma>, <3 RK_PD2 1 &pcfg_pull_none_8ma>, <3 RK_PD3 1 &pcfg_pull_none_8ma>;
            };
            lcdc_m0_sleep_pins: lcdc-m0-sleep-pins {
                rockchip,pins = <3 RK_PA0 RK_FUNC_GPIO &pcfg_pull_none>, <3 RK_PA1 RK_FUNC_GPIO &pcfg_pull_none>, <3 RK_PA2 RK_FUNC_GPIO &pcfg_pull_none>, <3 RK_PA3 RK_FUNC_GPIO &pcfg_pull_none>, <3 RK_PA4 RK_FUNC_GPIO &pcfg_pull_none>, <3 RK_PA5 RK_FUNC_GPIO &pcfg_pull_none>, <3 RK_PA6 RK_FUNC_GPIO &pcfg_pull_none>, <3 RK_PA7 RK_FUNC_GPIO &pcfg_pull_none>, <3 RK_PB0 RK_FUNC_GPIO &pcfg_pull_none>, <3 RK_PB1 RK_FUNC_GPIO &pcfg_pull_none>, <3 RK_PB2 RK_FUNC_GPIO &pcfg_pull_none>, <3 RK_PB3 RK_FUNC_GPIO &pcfg_pull_none>, <3 RK_PB4 RK_FUNC_GPIO &pcfg_pull_none>, <3 RK_PB5 RK_FUNC_GPIO &pcfg_pull_none>, <3 RK_PB6 RK_FUNC_GPIO &pcfg_pull_none>, <3 RK_PB7 RK_FUNC_GPIO &pcfg_pull_none>, <3 RK_PC0 RK_FUNC_GPIO &pcfg_pull_none>, <3 RK_PC1 RK_FUNC_GPIO &pcfg_pull_none>, <3 RK_PC2 RK_FUNC_GPIO &pcfg_pull_none>, <3 RK_PC3 RK_FUNC_GPIO &pcfg_pull_none>, <3 RK_PC4 RK_FUNC_GPIO &pcfg_pull_none>, <3 RK_PC5 RK_FUNC_GPIO &pcfg_pull_none>, <3 RK_PC6 RK_FUNC_GPIO &pcfg_pull_none>, <3 RK_PC7 RK_FUNC_GPIO &pcfg_pull_none>, <3 RK_PD0 RK_FUNC_GPIO &pcfg_pull_none>, <3 RK_PD1 RK_FUNC_GPIO &pcfg_pull_none>, <3 RK_PD2 RK_FUNC_GPIO &pcfg_pull_none>, <3 RK_PD3 RK_FUNC_GPIO &pcfg_pull_none>;
            };
            lcdc_m1_rgb_pins: lcdc-m1-rgb-pins {
                rockchip,pins = <3 RK_PA0 1 &pcfg_pull_none_8ma>, <3 RK_PA4 1 &pcfg_pull_none_8ma>, <3 RK_PA6 1 &pcfg_pull_none_8ma>, <3 RK_PB2 1 &pcfg_pull_none_8ma>, <3 RK_PB3 1 &pcfg_pull_none_8ma>, <3 RK_PB5 1 &pcfg_pull_none_8ma>, <3 RK_PC0 1 &pcfg_pull_none_8ma>, <3 RK_PC1 1 &pcfg_pull_none_8ma>, <3 RK_PC2 1 &pcfg_pull_none_8ma>, <3 RK_PC3 1 &pcfg_pull_none_8ma>, <3 RK_PC4 1 &pcfg_pull_none_8ma>, <3 RK_PC5 1 &pcfg_pull_none_8ma>, <3 RK_PC6 1 &pcfg_pull_none_8ma>, <3 RK_PC7 1 &pcfg_pull_none_8ma>, <3 RK_PD0 1 &pcfg_pull_none_8ma>, <3 RK_PD1 1 &pcfg_pull_none_8ma>, <3 RK_PD2 1 &pcfg_pull_none_8ma>, <3 RK_PD3 1 &pcfg_pull_none_8ma>;
            };
            lcdc_m1_sleep_pins: lcdc-m1-sleep-pins {
                rockchip,pins = <3 RK_PA0 RK_FUNC_GPIO &pcfg_pull_none>, <3 RK_PA4 RK_FUNC_GPIO &pcfg_pull_none>, <3 RK_PA6 RK_FUNC_GPIO &pcfg_pull_none>, <3 RK_PB2 RK_FUNC_GPIO &pcfg_pull_none>, <3 RK_PB3 RK_FUNC_GPIO &pcfg_pull_none>, <3 RK_PB5 RK_FUNC_GPIO &pcfg_pull_none>, <3 RK_PC0 RK_FUNC_GPIO &pcfg_pull_none>, <3 RK_PC1 RK_FUNC_GPIO &pcfg_pull_none>, <3 RK_PC2 RK_FUNC_GPIO &pcfg_pull_none>, <3 RK_PC3 RK_FUNC_GPIO &pcfg_pull_none>, <3 RK_PC4 RK_FUNC_GPIO &pcfg_pull_none>, <3 RK_PC5 RK_FUNC_GPIO &pcfg_pull_none>, <3 RK_PC6 RK_FUNC_GPIO &pcfg_pull_none>, <3 RK_PC7 RK_FUNC_GPIO &pcfg_pull_none>, <3 RK_PD0 RK_FUNC_GPIO &pcfg_pull_none>, <3 RK_PD1 RK_FUNC_GPIO &pcfg_pull_none>, <3 RK_PD2 RK_FUNC_GPIO &pcfg_pull_none>, <3 RK_PD3 RK_FUNC_GPIO &pcfg_pull_none>;
            };
        };
        pwm0 {
            pwm0_pin: pwm0-pin {
                rockchip,pins = <0 RK_PB7 1 &pcfg_pull_none>;
            };
        };
        pwm1 {
            pwm1_pin: pwm1-pin {
                rockchip,pins = <0 RK_PC0 1 &pcfg_pull_none>;
            };
        };
        pwm2 {
            pwm2_pin: pwm2-pin {
                rockchip,pins = <2 RK_PB5 1 &pcfg_pull_none>;
            };
        };
        pwm3 {
            pwm3_pin: pwm3-pin {
                rockchip,pins = <0 RK_PC1 1 &pcfg_pull_none>;
            };
        };
        pwm4 {
            pwm4_pin: pwm4-pin {
                rockchip,pins = <3 RK_PC2 3 &pcfg_pull_none>;
            };
        };
        pwm5 {
            pwm5_pin: pwm5-pin {
                rockchip,pins = <3 RK_PC3 3 &pcfg_pull_none>;
            };
        };
        pwm6 {
            pwm6_pin: pwm6-pin {
                rockchip,pins = <3 RK_PC4 3 &pcfg_pull_none>;
            };
        };
        pwm7 {
            pwm7_pin: pwm7-pin {
                rockchip,pins = <3 RK_PC5 3 &pcfg_pull_none>;
            };
        };
        gmac {
            rmii_pins: rmii-pins {
                rockchip,pins = <2 RK_PA0 2 &pcfg_pull_none_12ma>, <2 RK_PA1 2 &pcfg_pull_none_12ma>, <2 RK_PA2 2 &pcfg_pull_none_12ma>, <2 RK_PA3 2 &pcfg_pull_none>, <2 RK_PA4 2 &pcfg_pull_none>, <2 RK_PA5 2 &pcfg_pull_none>, <2 RK_PA6 2 &pcfg_pull_none>, <2 RK_PA7 2 &pcfg_pull_none>, <2 RK_PB1 2 &pcfg_pull_none>;
            };
            mac_refclk_12ma: mac-refclk-12ma {
                rockchip,pins = <2 RK_PB2 2 &pcfg_pull_none_12ma>;
            };
            mac_refclk: mac-refclk {
                rockchip,pins = <2 RK_PB2 2 &pcfg_pull_none>;
            };
        };
        cif-m0 {
            cif_clkout_m0: cif-clkout-m0 {
                rockchip,pins = <2 RK_PB3 1 &pcfg_pull_none_12ma>;
            };
            dvp_d2d9_m0: dvp-d2d9-m0 {
                rockchip,pins = <2 RK_PA0 1 &pcfg_pull_none>, <2 RK_PA1 1 &pcfg_pull_none>, <2 RK_PA2 1 &pcfg_pull_none>, <2 RK_PA3 1 &pcfg_pull_none>, <2 RK_PA4 1 &pcfg_pull_none>, <2 RK_PA5 1 &pcfg_pull_none>, <2 RK_PA6 1 &pcfg_pull_none>, <2 RK_PA7 1 &pcfg_pull_none>, <2 RK_PB0 1 &pcfg_pull_none>, <2 RK_PB1 1 &pcfg_pull_none>, <2 RK_PB2 1 &pcfg_pull_none>, <2 RK_PB3 1 &pcfg_pull_none>;
            };
            dvp_d0d1_m0: dvp-d0d1-m0 {
                rockchip,pins = <2 RK_PB4 1 &pcfg_pull_none>, <2 RK_PB6 1 &pcfg_pull_none>;
            };
            dvp_d10d11_m0: d10-d11-m0 {
                rockchip,pins = <2 RK_PB7 1 &pcfg_pull_none>, <2 RK_PC0 1 &pcfg_pull_none>;
            };
        };
        cif-m1 {
            cif_clkout_m1: cif-clkout-m1 {
                rockchip,pins = <3 RK_PD0 3 &pcfg_pull_none>;
            };
            dvp_d2d9_m1: dvp-d2d9-m1 {
                rockchip,pins = <3 RK_PA3 3 &pcfg_pull_none>, <3 RK_PA5 3 &pcfg_pull_none>, <3 RK_PA7 3 &pcfg_pull_none>, <3 RK_PB0 3 &pcfg_pull_none>, <3 RK_PB1 3 &pcfg_pull_none>, <3 RK_PB4 3 &pcfg_pull_none>, <3 RK_PB6 3 &pcfg_pull_none>, <3 RK_PB7 3 &pcfg_pull_none>, <3 RK_PD1 3 &pcfg_pull_none>, <3 RK_PD2 3 &pcfg_pull_none>, <3 RK_PD3 3 &pcfg_pull_none>, <3 RK_PD0 3 &pcfg_pull_none>;
            };
            dvp_d0d1_m1: dvp-d0d1-m1 {
                rockchip,pins = <3 RK_PA1 3 &pcfg_pull_none>, <3 RK_PA2 3 &pcfg_pull_none>;
            };
            dvp_d10d11_m1: d10-d11-m1 {
                rockchip,pins = <3 RK_PC6 3 &pcfg_pull_none>, <3 RK_PC7 3 &pcfg_pull_none>;
            };
        };
        isp {
            isp_prelight: isp-prelight {
                rockchip,pins = <3 RK_PD1 4 &pcfg_pull_none>;
            };
        };
        pcfg_pull_none_n_4ma: pcfg-pull-none-n-4ma {
            bias-disable;
            drive-strength-s = <4>;
        };
        pcfg_pull_up_n_4ma: pcfg-pull-up-n-4ma {
            bias-pull-up;
            drive-strength-s = <4>;
        };
        pcfg_pull_down_n_4ma: pcfg-pull-down-n-4ma {
            bias-pull-down;
            drive-strength-s = <4>;
        };
        pcfg_pull_none_0_6ma: pcfg-pull-none-0-6ma {
            bias-disable;
            drive-strength-s = <6>;
        };
        pcfg_pull_up_0_6ma: pcfg-pull-up-0-6ma {
            bias-pull-up;
            drive-strength-s = <6>;
        };
        pcfg_pull_down_0_6ma: pcfg-pull-down-0-6ma {
            bias-pull-down;
            drive-strength-s = <6>;
        };
        pcfg_pull_none_4_6ma: pcfg-pull-none-4-6ma {
            bias-disable;
            drive-strength = <4>;
            drive-strength-s = <6>;
        };
        pcfg_pull_up_4_6ma: pcfg-pull-up-4-6ma {
            bias-pull-up;
            drive-strength = <4>;
            drive-strength-s = <6>;
        };
        pcfg_pull_down_4_6ma: pcfg-pull-down-4-6ma {
            bias-pull-down;
            drive-strength = <4>;
            drive-strength-s = <6>;
        };
        pcfg_pull_none_8_6ma: pcfg-pull-none-8-6ma {
            bias-disable;
            drive-strength = <8>;
            drive-strength-s = <6>;
        };
        pcfg_pull_up_8_6ma: pcfg-pull-up-8-6ma {
            bias-pull-up;
            drive-strength = <8>;
            drive-strength-s = <6>;
        };
        pcfg_pull_down_8_6ma: pcfg-pull-down-8-6ma {
            bias-pull-down;
            drive-strength = <8>;
            drive-strength-s = <6>;
        };
        pcfg_pull_none_8_4ma: pcfg-pull-none-8-4ma {
            bias-disable;
            drive-strength = <8>;
            drive-strength-s = <4>;
        };
        pcfg_pull_up_8_4ma: pcfg-pull-up-8-4ma {
            bias-pull-up;
            drive-strength = <8>;
            drive-strength-s = <4>;
        };
        pcfg_pull_down_8_4ma: pcfg-pull-down-8-4ma {
            bias-pull-down;
            drive-strength = <8>;
            drive-strength-s = <4>;
        };
        pcfg_pull_none_12_4ma: pcfg-pull-none-12-4ma {
            bias-disable;
            drive-strength = <12>;
            drive-strength-s = <4>;
        };
        pcfg_pull_up_12_4ma: pcfg-pull-up-12-4ma {
            bias-pull-up;
            drive-strength = <12>;
            drive-strength-s = <4>;
        };
        pcfg_pull_down_12_4ma: pcfg-pull-down-12-4ma {
            bias-pull-down;
            drive-strength = <12>;
            drive-strength-s = <4>;
        };
        pcfg_pull_none_12_6ma: pcfg-pull-none-12-6ma {
            bias-disable;
            drive-strength = <12>;
            drive-strength-s = <6>;
        };
        pcfg_pull_up_12_6ma: pcfg-pull-up-12-6ma {
            bias-pull-up;
            drive-strength = <12>;
            drive-strength-s = <6>;
        };
        pcfg_pull_down_12_6ma: pcfg-pull-down-12-6ma {
            bias-pull-down;
            drive-strength = <12>;
            drive-strength-s = <6>;
        };
        headphone {
            hp_det: hp-det {
                rockchip,pins = <2 RK_PC6 RK_FUNC_GPIO &pcfg_pull_none>;
            };
        };
        led {
            led_gpio: led-gpio {
                rockchip,pins = <1 RK_PB2 RK_FUNC_GPIO &pcfg_pull_none>, <1 RK_PB4 RK_FUNC_GPIO &pcfg_pull_none>, <1 RK_PB5 RK_FUNC_GPIO &pcfg_pull_none>, <1 RK_PB6 RK_FUNC_GPIO &pcfg_pull_none>, <1 RK_PB7 RK_FUNC_GPIO &pcfg_pull_none>;
            };
        };
        pmic {
            pmic_int: pmic_int {
                rockchip,pins = <0 RK_PB2 RK_FUNC_GPIO &pcfg_pull_up>;
            };
            soc_slppin_gpio: soc_slppin_gpio {
                rockchip,pins = <0 RK_PA4 RK_FUNC_GPIO &pcfg_output_low>;
            };
            soc_slppin_slp: soc_slppin_slp {
                rockchip,pins = <0 RK_PA4 1 &pcfg_pull_none>;
            };
            soc_slppin_rst: soc_slppin_rst {
                rockchip,pins = <0 RK_PA4 2 &pcfg_pull_none>;
            };
        };
        btns {
            btn_pins: btn-pins {
                rockchip,pins = <3 RK_PB5 RK_FUNC_GPIO &pcfg_pull_up>, <3 RK_PC4 RK_FUNC_GPIO &pcfg_pull_up>, <3 RK_PB3 RK_FUNC_GPIO &pcfg_pull_up>, <3 RK_PA4 RK_FUNC_GPIO &pcfg_pull_up>, <3 RK_PD1 RK_FUNC_GPIO &pcfg_pull_up>, <3 RK_PD2 RK_FUNC_GPIO &pcfg_pull_up>, <3 RK_PA5 RK_FUNC_GPIO &pcfg_pull_up>, <3 RK_PA6 RK_FUNC_GPIO &pcfg_pull_up>, <3 RK_PC5 RK_FUNC_GPIO &pcfg_pull_up>, <3 RK_PD3 RK_FUNC_GPIO &pcfg_pull_up>, <3 RK_PC2 RK_FUNC_GPIO &pcfg_pull_up>, <3 RK_PC0 RK_FUNC_GPIO &pcfg_pull_up>, <3 RK_PC1 RK_FUNC_GPIO &pcfg_pull_up>, <3 RK_PB2 RK_FUNC_GPIO &pcfg_pull_up>, <3 RK_PC3 RK_FUNC_GPIO &pcfg_pull_up>;
            };
        };
        eeprom {
            eeprom_wp_gpio: eeprom-wp-gpio {
                rockchip,pins = <2 RK_PB5 RK_FUNC_GPIO &pcfg_pull_up>;
            };
        };
        dsi0-lcd {
            dsi0_lcd_gpio: dsi0-lcd-gpio {
                rockchip,pins = <0 RK_PC1 RK_FUNC_GPIO &pcfg_pull_none>, <0 RK_PB4 RK_FUNC_GPIO &pcfg_pull_up>;
            };
        };
        keys {
            volume_gpio: volume-gpio {
                rockchip,pins = <3 RK_PB4 RK_FUNC_GPIO &pcfg_pull_up>, <3 RK_PB6 RK_FUNC_GPIO &pcfg_pull_up>;
            };
        };
    };
    chosen {
    };
    fiq-debugger {
        compatible = "rockchip,fiq-debugger";
        rockchip,serial-id = <2>;
        rockchip,wake-irq = <0>;
        rockchip,irq-mode-enable = <0>;
        rockchip,baudrate = <1500000>;
        interrupts = <GIC_SPI 127 IRQ_TYPE_LEVEL_LOW>;
        pinctrl-names = "default";
        pinctrl-0 = <&uart2m1_xfer>;
        status = "okay";
    };
    reserved-memory {
        #address-cells = <2>;
        #size-cells = <2>;
        ranges;
        drm_logo: drm-logo@00000000 {
            compatible = "rockchip,drm-logo";
            reg = <0x0 0x0 0 0x0>;
        };
        ramoops: ramoops@110000 {
            compatible = "ramoops";
            reg = <0x0 0x110000 0 0xf0000>;
            record-size = <131072>;
            console-size = <524288>;
            ftrace-size = <0>;
            pmsg-size = <327680>;
        };
    };
    keys: gpio-keys {
        compatible = "gpio-keys";
        pinctrl-names = "default";
        pinctrl-0 = <&volume_gpio>;
        autorepeat;
        vol-up-key {
            gpios = <&gpio3 RK_PB4 GPIO_ACTIVE_LOW>;
            linux,code = <115>;
            label = "volume up";
        };
        vol-down-key {
            gpios = <&gpio3 RK_PB6 GPIO_ACTIVE_LOW>;
            linux,code = <114>;
            label = "volume down";
        };
    };
    joypad: gamekiddy-joypad {
        compatible = "gamekiddy-joypad";
        joypad-name = "pixel2_joypad";
        joypad-vendor = <1>;
        joypad-product = <8450>;
        joypad-revision = <256>;
        pinctrl-names = "default";
        pinctrl-0 = <&btn_pins>;
        io-channel-names = "joy1_x", "joy1_y", "joy2_x", "joy2_y";
        io-channels = <&saradc 1>, <&saradc 0>, <&saradc 2>, <&saradc 3>;
        button-adc-count = <4>;
        button-adc-scale = <2>;
        button-adc-deadzone = <20>;
        button-adc-x-range = <1800>;
        button-adc-y-range = <1800>;
        button-adc-fuzz = <32>;
        button-adc-flat = <32>;
        poll-interval = <10>;
        sw1 {
            gpios = <&gpio3 RK_PB5 GPIO_ACTIVE_LOW>;
            label = "GPIO DPAD-UP";
            linux,code = <544>;
        };
        sw2 {
            gpios = <&gpio3 RK_PC4 GPIO_ACTIVE_LOW>;
            label = "GPIO DPAD-DOWN";
            linux,code = <545>;
        };
        sw3 {
            gpios = <&gpio3 RK_PB3 GPIO_ACTIVE_LOW>;
            label = "GPIO DPAD-LEFT";
            linux,code = <546>;
        };
        sw4 {
            gpios = <&gpio3 RK_PA4 GPIO_ACTIVE_LOW>;
            label = "GPIO DPAD-RIGHT";
            linux,code = <547>;
        };
        sw5 {
            gpios = <&gpio3 RK_PD1 GPIO_ACTIVE_LOW>;
            label = "GPIO KEY BTN-A";
            linux,code = <305>;
        };
        sw6 {
            gpios = <&gpio3 RK_PD2 GPIO_ACTIVE_LOW>;
            label = "GPIO BTN-B";
            linux,code = <304>;
        };
        sw7 {
            gpios = <&gpio3 RK_PA6 GPIO_ACTIVE_LOW>;
            label = "GPIO BTN-Y";
            linux,code = <308>;
        };
        sw8 {
            gpios = <&gpio3 RK_PA5 GPIO_ACTIVE_LOW>;
            label = "GPIO BTN-X";
            linux,code = <307>;
        };
        sw9 {
            gpios = <&gpio3 RK_PC5 GPIO_ACTIVE_LOW>;
            label = "GPIO F1";
            linux,code = <704>;
        };
        sw11 {
            gpios = <&gpio3 RK_PC2 GPIO_ACTIVE_LOW>;
            label = "GPIO BTN_SELECT";
            linux,code = <314>;
        };
        sw12 {
            gpios = <&gpio3 RK_PD3 GPIO_ACTIVE_LOW>;
            label = "GPIO BTN_START";
            linux,code = <315>;
        };
        sw15 {
            gpios = <&gpio3 RK_PC0 GPIO_ACTIVE_LOW>;
            label = "GPIO TOP-LEFT";
            linux,code = <310>;
        };
        sw16 {
            gpios = <&gpio3 RK_PB2 GPIO_ACTIVE_LOW>;
            label = "GPIO TOP-RIGHT";
            linux,code = <311>;
        };
        sw20 {
            gpios = <&gpio3 RK_PC1 GPIO_ACTIVE_LOW>;
            label = "GPIO TOP-LEFT2";
            linux,code = <312>;
        };
        sw21 {
            gpios = <&gpio3 RK_PC3 GPIO_ACTIVE_LOW>;
            label = "GPIO TOP-RIGHT2";
            linux,code = <313>;
        };
    };
    backlight: backlight {
        compatible = "pwm-backlight";
        pwms = <&pwm1 0 25000 1>;
        brightness-levels = <0 1 2 3 4 5 6 7 8 9 10 11 12 13 14 15 16 17 18 19 20 21 22 23 24 25 26 27 28 29 30 31 32 33 34 35 36 37 38 39 40 41 42 43 44 45 46 47 48 49 50 51 52 53 54 55 56 57 58 59 60 61 62 63 64 65 66 67 68 69 70 71 72 73 74 75 76 77 78 79 80 81 82 83 84 85 86 87 88 89 90 91 92 93 94 95 96 97 98 99 100 101 102 103 104 105 106 107 108 109 110 111 112 113 114 115 116 117 118 119 120 121 122 123 124 125 126 127 128 129 130 131 132 133 134 135 136 137 138 139 140 141 142 143 144 145 146 147 148 149 150 151 152 153 154 155 156 157 158 159 160 161 162 163 164 165 166 167 168 169 170 171 172 173 174 175 176 177 178 179 180 181 182 183 184 185 186 187 188 189 190 191 192 193 194 195 196 197 198 199 200 201 202 203 204 205 206 207 208 209 210 211 212 213 214 215 216 217 218 219 220 221 222 223 224 225 226 227 228 229 230 231 232 233 234 235 236 237 238 239 240 241 242 243 244 245 246 247 248 249 250 251 252 253 254 255>;
        default-brightness-level = <200>;
    };
    rk817-sound {
        status = "okay";
        compatible = "rockchip,multicodecs-card";
        rockchip,card-name = "rockchip-rk817";
        rockchip,format = "i2s";
        rockchip,mclk-fs = <256>;
        rockchip,cpu = <&i2s1_2ch>;
        rockchip,codec = <&rk817_codec>;
    };
    vccsys: vccsys {
        compatible = "regulator-fixed";
        regulator-name = "vcc3v8_sys";
        regulator-always-on;
        regulator-boot-on;
        regulator-min-microvolt = <3800000>;
        regulator-max-microvolt = <3800000>;
    };
    vibrator {
        compatible = "pwm-vibrator";
        pwms = <&pwm0 0 200000000 0>;
        pwm-names = "enable";
        direction-duty-cycle-ns = <200000000>;
    };
    vcc_mipi_lcd0: vcc-mipi-lcd0 {
        status = "okay";
        compatible = "regulator-fixed";
        regulator-name = "vcc_mipi_lcd0";
        gpio = <&gpio0 RK_PB5 GPIO_ACTIVE_LOW>;
        regulator-boot-on;
        regulator-state-mem {
            regulator-off-in-suspend;
        };
    };
};
